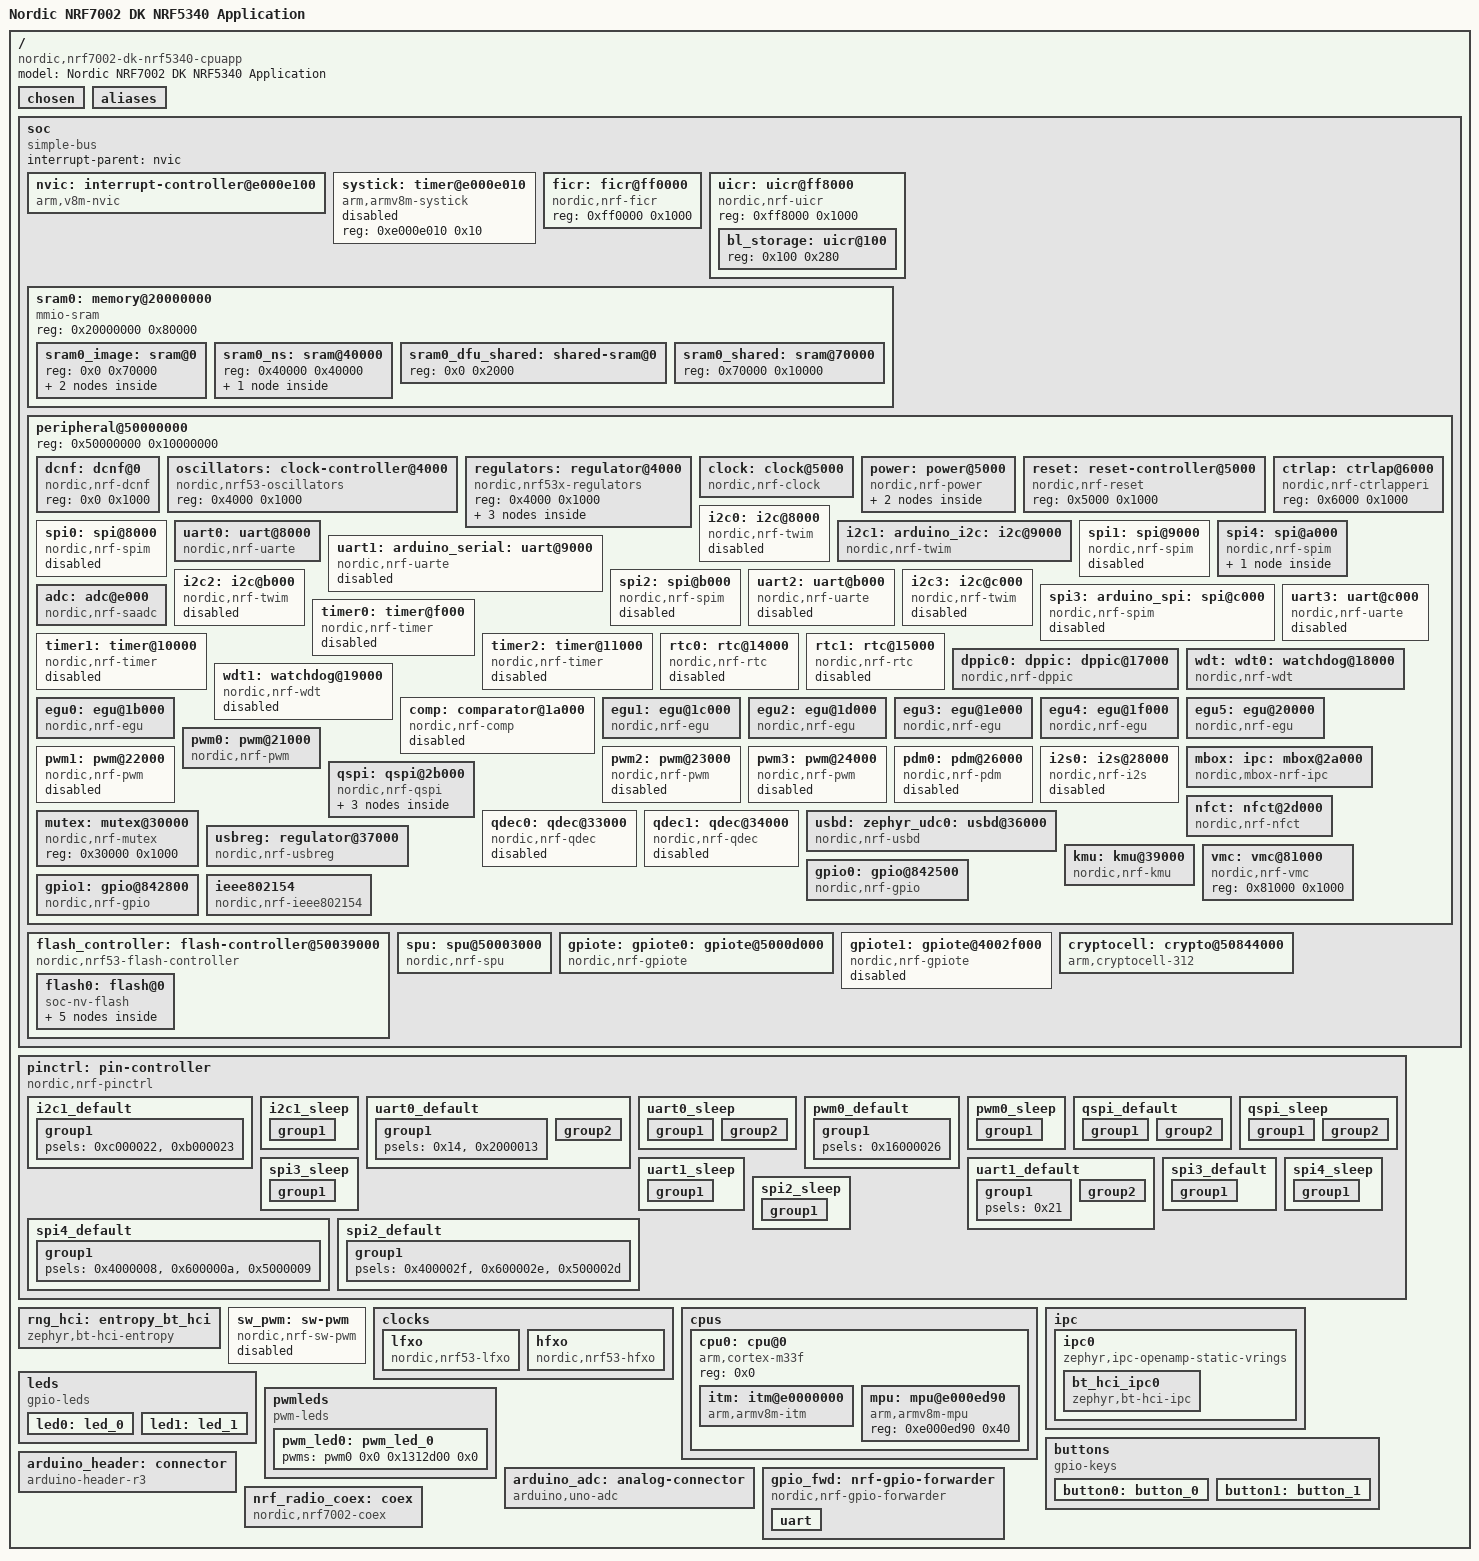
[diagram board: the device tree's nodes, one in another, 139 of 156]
/dts-v1/;

/* node '/' defined in zephyr/dts/common/skeleton.dtsi:9 */
/ {
	#address-cells = < 0x1 >;                        /* in zephyr/dts/common/skeleton.dtsi:10 */
	#size-cells = < 0x1 >;                           /* in zephyr/dts/common/skeleton.dtsi:11 */
	model = "Nordic NRF7002 DK NRF5340 Application"; /* in zephyr/boards/nordic/nrf7002dk/nrf7002dk_nrf5340_cpuapp.dts:13 */
	compatible = "nordic,nrf7002-dk-nrf5340-cpuapp"; /* in zephyr/boards/nordic/nrf7002dk/nrf7002dk_nrf5340_cpuapp.dts:14 */

	/* node '/chosen' defined in zephyr/dts/common/skeleton.dtsi:13 */
	chosen {
		zephyr,entropy = &cryptocell;                 /* in zephyr/dts/arm/nordic/nrf5340_cpuapp.dtsi:38 */
		zephyr,flash-controller = &flash_controller;  /* in zephyr/dts/arm/nordic/nrf5340_cpuapp.dtsi:39 */
		zephyr,console = &uart0;                      /* in zephyr/boards/nordic/nrf7002dk/nrf5340_cpuapp_common.dtsi:12 */
		zephyr,shell-uart = &uart0;                   /* in zephyr/boards/nordic/nrf7002dk/nrf5340_cpuapp_common.dtsi:13 */
		zephyr,uart-mcumgr = &uart0;                  /* in zephyr/boards/nordic/nrf7002dk/nrf5340_cpuapp_common.dtsi:14 */
		zephyr,bt-mon-uart = &uart0;                  /* in zephyr/boards/nordic/nrf7002dk/nrf5340_cpuapp_common.dtsi:15 */
		zephyr,bt-c2h-uart = &uart0;                  /* in zephyr/boards/nordic/nrf7002dk/nrf5340_cpuapp_common.dtsi:16 */
		zephyr,bt-hci = &bt_hci_ipc0;                 /* in zephyr/boards/nordic/nrf7002dk/nrf5340_cpuapp_common.dtsi:17 */
		nordic,802154-spinel-ipc = &ipc0;             /* in zephyr/boards/nordic/nrf7002dk/nrf5340_cpuapp_common.dtsi:18 */
		zephyr,ieee802154 = &ieee802154;              /* in zephyr/boards/nordic/nrf7002dk/nrf5340_cpuapp_common.dtsi:19 */
		zephyr,sram = &sram0_image;                   /* in zephyr/boards/nordic/nrf7002dk/nrf7002dk_nrf5340_cpuapp.dts:17 */
		zephyr,flash = &flash0;                       /* in zephyr/boards/nordic/nrf7002dk/nrf7002dk_nrf5340_cpuapp.dts:18 */
		zephyr,sram-secure-partition = &sram0_s;      /* in zephyr/boards/nordic/nrf7002dk/nrf7002dk_nrf5340_cpuapp.dts:20 */
		zephyr,sram-non-secure-partition = &sram0_ns; /* in zephyr/boards/nordic/nrf7002dk/nrf7002dk_nrf5340_cpuapp.dts:21 */
		zephyr,wifi = &wlan0;                         /* in zephyr/boards/nordic/nrf7002dk/nrf7002dk_nrf5340_cpuapp.dts:22 */
		zephyr,ipc_shm = &sram0_shared;               /* in zephyr/dts/vendor/nordic/nrf5340_shared_sram_partition.dtsi:22 */
		zephyr,code-partition = &boot_partition;      /* in bootloader/mcuboot/boot/zephyr/app.overlay:3 */
	};

	/* node '/aliases' defined in zephyr/dts/common/skeleton.dtsi:15 */
	aliases {
		led0 = &led0;               /* in zephyr/boards/nordic/nrf7002dk/nrf5340_cpuapp_common.dtsi:111 */
		led1 = &led1;               /* in zephyr/boards/nordic/nrf7002dk/nrf5340_cpuapp_common.dtsi:112 */
		pwm-led0 = &pwm_led0;       /* in zephyr/boards/nordic/nrf7002dk/nrf5340_cpuapp_common.dtsi:113 */
		sw0 = &button0;             /* in zephyr/boards/nordic/nrf7002dk/nrf5340_cpuapp_common.dtsi:114 */
		sw1 = &button1;             /* in zephyr/boards/nordic/nrf7002dk/nrf5340_cpuapp_common.dtsi:115 */
		mcuboot-button0 = &button0; /* in zephyr/boards/nordic/nrf7002dk/nrf5340_cpuapp_common.dtsi:116 */
		mcuboot-led0 = &led0;       /* in zephyr/boards/nordic/nrf7002dk/nrf5340_cpuapp_common.dtsi:117 */
		watchdog0 = &wdt0;          /* in zephyr/boards/nordic/nrf7002dk/nrf5340_cpuapp_common.dtsi:118 */
	};

	/* node '/soc' defined in zephyr/dts/arm/armv8-m.dtsi:6 */
	soc {
		#address-cells = < 0x1 >;     /* in zephyr/dts/arm/armv8-m.dtsi:7 */
		#size-cells = < 0x1 >;        /* in zephyr/dts/arm/armv8-m.dtsi:8 */
		interrupt-parent = < &nvic >; /* in zephyr/dts/arm/armv8-m.dtsi:10 */
		ranges;                       /* in zephyr/dts/arm/armv8-m.dtsi:11 */
		compatible = "simple-bus";    /* in zephyr/dts/arm/nordic/nrf5340_cpuapp.dtsi:43 */

		/* node '/soc/interrupt-controller@e000e100' defined in zephyr/dts/arm/armv8-m.dtsi:13 */
		nvic: interrupt-controller@e000e100 {
			#address-cells = < 0x1 >;            /* in zephyr/dts/arm/armv8-m.dtsi:14 */
			compatible = "arm,v8m-nvic";         /* in zephyr/dts/arm/armv8-m.dtsi:15 */
			reg = < 0xe000e100 0xc00 >;          /* in zephyr/dts/arm/armv8-m.dtsi:16 */
			interrupt-controller;                /* in zephyr/dts/arm/armv8-m.dtsi:17 */
			#interrupt-cells = < 0x2 >;          /* in zephyr/dts/arm/armv8-m.dtsi:18 */
			arm,num-irq-priority-bits = < 0x3 >; /* in zephyr/dts/arm/nordic/nrf5340_cpuapp.dtsi:152 */
			phandle = < 0x1 >;                   /* in zephyr/dts/arm/armv8-m.dtsi:10 */
		};

		/* node '/soc/timer@e000e010' defined in zephyr/dts/arm/armv8-m.dtsi:21 */
		systick: timer@e000e010 {
			compatible = "arm,armv8m-systick"; /* in zephyr/dts/arm/armv8-m.dtsi:22 */
			reg = < 0xe000e010 0x10 >;         /* in zephyr/dts/arm/armv8-m.dtsi:23 */
			status = "disabled";               /* in zephyr/dts/arm/nordic/nrf5340_cpuapp.dtsi:157 */
		};

		/* node '/soc/ficr@ff0000' defined in zephyr/dts/arm/nordic/nrf5340_cpuapp.dtsi:45 */
		ficr: ficr@ff0000 {
			compatible = "nordic,nrf-ficr"; /* in zephyr/dts/arm/nordic/nrf5340_cpuapp.dtsi:46 */
			reg = < 0xff0000 0x1000 >;      /* in zephyr/dts/arm/nordic/nrf5340_cpuapp.dtsi:47 */
			#nordic,ficr-cells = < 0x1 >;   /* in zephyr/dts/arm/nordic/nrf5340_cpuapp.dtsi:48 */
			status = "okay";                /* in zephyr/dts/arm/nordic/nrf5340_cpuapp.dtsi:49 */
		};

		/* node '/soc/uicr@ff8000' defined in zephyr/dts/arm/nordic/nrf5340_cpuapp.dtsi:52 */
		uicr: uicr@ff8000 {
			compatible = "nordic,nrf-uicr";   /* in zephyr/dts/arm/nordic/nrf5340_cpuapp.dtsi:53 */
			reg = < 0xff8000 0x1000 >;        /* in zephyr/dts/arm/nordic/nrf5340_cpuapp.dtsi:54 */
			ranges = < 0x0 0xff8000 0x1000 >; /* in zephyr/dts/arm/nordic/nrf5340_cpuapp.dtsi:55 */
			status = "okay";                  /* in zephyr/dts/arm/nordic/nrf5340_cpuapp.dtsi:56 */
			#address-cells = < 0x1 >;         /* in zephyr/dts/arm/nordic/nrf5340_cpuapp.dtsi:57 */
			#size-cells = < 0x1 >;            /* in zephyr/dts/arm/nordic/nrf5340_cpuapp.dtsi:58 */

			/* node '/soc/uicr@ff8000/uicr@100' defined in zephyr/dts/vendor/nordic/nrf5340_cpuapp_partition.dtsi:43 */
			bl_storage: uicr@100 {
				reg = < 0x100 0x280 >; /* in zephyr/dts/vendor/nordic/nrf5340_cpuapp_partition.dtsi:44 */
			};
		};

		/* node '/soc/memory@20000000' defined in zephyr/dts/arm/nordic/nrf5340_cpuapp.dtsi:61 */
		sram0: memory@20000000 {
			compatible = "mmio-sram";            /* in zephyr/dts/arm/nordic/nrf5340_cpuapp.dtsi:62 */
			#address-cells = < 0x1 >;            /* in zephyr/dts/arm/nordic/nrf5340_cpuapp.dtsi:63 */
			#size-cells = < 0x1 >;               /* in zephyr/dts/arm/nordic/nrf5340_cpuapp.dtsi:64 */
			reg = < 0x20000000 0x80000 >;        /* in zephyr/dts/arm/nordic/nrf5340_cpuapp_qkaa.dtsi:11 */
			ranges = < 0x0 0x20000000 0x80000 >; /* in zephyr/dts/arm/nordic/nrf5340_cpuapp_qkaa.dtsi:12 */

			/* node '/soc/memory@20000000/sram@0' defined in zephyr/dts/vendor/nordic/nrf5340_sram_partition.dtsi:16 */
			sram0_image: sram@0 {
				reg = < 0x0 0x70000 >;        /* in zephyr/dts/vendor/nordic/nrf5340_sram_partition.dtsi:18 */
				ranges = < 0x0 0x0 0x70000 >; /* in zephyr/dts/vendor/nordic/nrf5340_sram_partition.dtsi:19 */
				#address-cells = < 0x1 >;     /* in zephyr/dts/vendor/nordic/nrf5340_sram_partition.dtsi:20 */
				#size-cells = < 0x1 >;        /* in zephyr/dts/vendor/nordic/nrf5340_sram_partition.dtsi:21 */

				/* node '/soc/memory@20000000/sram@0/sram0_image@0' defined in zephyr/dts/vendor/nordic/nrf5340_sram_partition.dtsi:23 */
				sram0_s: sram0_image@0 {
					reg = < 0x0 0x40000 >; /* in zephyr/dts/vendor/nordic/nrf5340_sram_partition.dtsi:25 */
				};

				/* node '/soc/memory@20000000/sram@0/sram@2000' defined in zephyr/dts/vendor/nordic/nrf5340_sram_partition.dtsi:28 */
				sram0_offset_for_dfu: sram@2000 {
					reg = < 0x2000 0x6e000 >;        /* in zephyr/dts/vendor/nordic/nrf5340_sram_partition.dtsi:29 */
					ranges = < 0x0 0x2000 0x6e000 >; /* in zephyr/dts/vendor/nordic/nrf5340_sram_partition.dtsi:30 */
					#address-cells = < 0x1 >;        /* in zephyr/dts/vendor/nordic/nrf5340_sram_partition.dtsi:31 */
					#size-cells = < 0x1 >;           /* in zephyr/dts/vendor/nordic/nrf5340_sram_partition.dtsi:32 */
				};
			};

			/* node '/soc/memory@20000000/sram@40000' defined in zephyr/dts/vendor/nordic/nrf5340_sram_partition.dtsi:40 */
			sram0_ns: sram@40000 {
				reg = < 0x40000 0x40000 >;        /* in zephyr/dts/vendor/nordic/nrf5340_sram_partition.dtsi:42 */
				ranges = < 0x0 0x40000 0x40000 >; /* in zephyr/dts/vendor/nordic/nrf5340_sram_partition.dtsi:43 */
				#address-cells = < 0x1 >;         /* in zephyr/dts/vendor/nordic/nrf5340_sram_partition.dtsi:44 */
				#size-cells = < 0x1 >;            /* in zephyr/dts/vendor/nordic/nrf5340_sram_partition.dtsi:45 */

				/* node '/soc/memory@20000000/sram@40000/sram0_ns@0' defined in zephyr/dts/vendor/nordic/nrf5340_sram_partition.dtsi:47 */
				sram0_ns_app: sram0_ns@0 {
					reg = < 0x0 0x30000 >; /* in zephyr/dts/vendor/nordic/nrf5340_sram_partition.dtsi:49 */
				};
			};

			/* node '/soc/memory@20000000/shared-sram@0' defined in zephyr/dts/vendor/nordic/nrf5340_shared_sram_partition.dtsi:27 */
			sram0_dfu_shared: shared-sram@0 {
				reg = < 0x0 0x2000 >; /* in zephyr/dts/vendor/nordic/nrf5340_shared_sram_partition.dtsi:28 */
			};

			/* node '/soc/memory@20000000/sram@70000' defined in zephyr/dts/vendor/nordic/nrf5340_shared_sram_partition.dtsi:31 */
			sram0_shared: sram@70000 {
				reg = < 0x70000 0x10000 >; /* in zephyr/dts/vendor/nordic/nrf5340_shared_sram_partition.dtsi:33 */
				phandle = < 0x15 >;        /* in zephyr/dts/arm/nordic/nrf5340_cpuapp_ipc.dtsi:9 */
			};
		};

		/* node '/soc/peripheral@50000000' defined in zephyr/dts/arm/nordic/nrf5340_cpuapp.dtsi:67 */
		peripheral@50000000 {
			reg = < 0x50000000 0x10000000 >;               /* in zephyr/dts/arm/nordic/nrf5340_cpuapp.dtsi:68 */
			#address-cells = < 0x1 >;                      /* in zephyr/dts/arm/nordic/nrf5340_cpuapp.dtsi:69 */
			#size-cells = < 0x1 >;                         /* in zephyr/dts/arm/nordic/nrf5340_cpuapp.dtsi:70 */
			ranges = < 0x0 0x50000000 0x10000000 >,
			         < 0x10000000 0x10000000 0x10000000 >; /* in zephyr/dts/arm/nordic/nrf5340_cpuapp.dtsi:71 */

			/* node '/soc/peripheral@50000000/dcnf@0' defined in zephyr/dts/arm/nordic/nrf5340_cpuapp_peripherals.dtsi:9 */
			dcnf: dcnf@0 {
				compatible = "nordic,nrf-dcnf"; /* in zephyr/dts/arm/nordic/nrf5340_cpuapp_peripherals.dtsi:10 */
				reg = < 0x0 0x1000 >;           /* in zephyr/dts/arm/nordic/nrf5340_cpuapp_peripherals.dtsi:11 */
				status = "okay";                /* in zephyr/dts/arm/nordic/nrf5340_cpuapp_peripherals.dtsi:12 */
			};

			/* node '/soc/peripheral@50000000/clock-controller@4000' defined in zephyr/dts/arm/nordic/nrf5340_cpuapp_peripherals.dtsi:15 */
			oscillators: clock-controller@4000 {
				compatible = "nordic,nrf53-oscillators"; /* in zephyr/dts/arm/nordic/nrf5340_cpuapp_peripherals.dtsi:16 */
				reg = < 0x4000 0x1000 >;                 /* in zephyr/dts/arm/nordic/nrf5340_cpuapp_peripherals.dtsi:17 */
			};

			/* node '/soc/peripheral@50000000/regulator@4000' defined in zephyr/dts/arm/nordic/nrf5340_cpuapp_peripherals.dtsi:20 */
			regulators: regulator@4000 {
				compatible = "nordic,nrf53x-regulators"; /* in zephyr/dts/arm/nordic/nrf5340_cpuapp_peripherals.dtsi:21 */
				reg = < 0x4000 0x1000 >;                 /* in zephyr/dts/arm/nordic/nrf5340_cpuapp_peripherals.dtsi:22 */
				status = "okay";                         /* in zephyr/dts/arm/nordic/nrf5340_cpuapp_peripherals.dtsi:23 */
				#address-cells = < 0x1 >;                /* in zephyr/dts/arm/nordic/nrf5340_cpuapp_peripherals.dtsi:24 */
				#size-cells = < 0x1 >;                   /* in zephyr/dts/arm/nordic/nrf5340_cpuapp_peripherals.dtsi:25 */

				/* node '/soc/peripheral@50000000/regulator@4000/regulator@4704' defined in zephyr/dts/arm/nordic/nrf5340_cpuapp_peripherals.dtsi:27 */
				vregmain: regulator@4704 {
					compatible = "nordic,nrf5x-regulator"; /* in zephyr/dts/arm/nordic/nrf5340_cpuapp_peripherals.dtsi:28 */
					reg = < 0x4704 0x1 >;                  /* in zephyr/dts/arm/nordic/nrf5340_cpuapp_peripherals.dtsi:29 */
					status = "okay";                       /* in zephyr/dts/arm/nordic/nrf5340_cpuapp_peripherals.dtsi:30 */
					regulator-name = "VREGMAIN";           /* in zephyr/dts/arm/nordic/nrf5340_cpuapp_peripherals.dtsi:31 */
					regulator-initial-mode = < 0x1 >;      /* in zephyr/boards/nordic/nrf7002dk/nrf5340_cpuapp_common.dtsi:132 */
				};

				/* node '/soc/peripheral@50000000/regulator@4000/regulator@4904' defined in zephyr/dts/arm/nordic/nrf5340_cpuapp_peripherals.dtsi:35 */
				vregradio: regulator@4904 {
					compatible = "nordic,nrf5x-regulator"; /* in zephyr/dts/arm/nordic/nrf5340_cpuapp_peripherals.dtsi:36 */
					reg = < 0x4904 0x1 >;                  /* in zephyr/dts/arm/nordic/nrf5340_cpuapp_peripherals.dtsi:37 */
					status = "okay";                       /* in zephyr/dts/arm/nordic/nrf5340_cpuapp_peripherals.dtsi:38 */
					regulator-name = "VREGRADIO";          /* in zephyr/dts/arm/nordic/nrf5340_cpuapp_peripherals.dtsi:39 */
					regulator-initial-mode = < 0x1 >;      /* in zephyr/boards/nordic/nrf7002dk/nrf5340_cpuapp_common.dtsi:136 */
				};

				/* node '/soc/peripheral@50000000/regulator@4000/regulator@4b00' defined in zephyr/dts/arm/nordic/nrf5340_cpuapp_peripherals.dtsi:43 */
				vregh: regulator@4b00 {
					compatible = "nordic,nrf53x-regulator-hv"; /* in zephyr/dts/arm/nordic/nrf5340_cpuapp_peripherals.dtsi:44 */
					reg = < 0x4b00 0x44 >;                     /* in zephyr/dts/arm/nordic/nrf5340_cpuapp_peripherals.dtsi:45 */
					regulator-name = "VREGH";                  /* in zephyr/dts/arm/nordic/nrf5340_cpuapp_peripherals.dtsi:47 */
					status = "okay";                           /* in zephyr/boards/nordic/nrf7002dk/nrf5340_cpuapp_common.dtsi:140 */
				};
			};

			/* node '/soc/peripheral@50000000/clock@5000' defined in zephyr/dts/arm/nordic/nrf5340_cpuapp_peripherals.dtsi:51 */
			clock: clock@5000 {
				compatible = "nordic,nrf-clock"; /* in zephyr/dts/arm/nordic/nrf5340_cpuapp_peripherals.dtsi:52 */
				reg = < 0x5000 0x1000 >;         /* in zephyr/dts/arm/nordic/nrf5340_cpuapp_peripherals.dtsi:53 */
				interrupts = < 0x5 0x1 >;        /* in zephyr/dts/arm/nordic/nrf5340_cpuapp_peripherals.dtsi:54 */
				status = "okay";                 /* in zephyr/dts/arm/nordic/nrf5340_cpuapp_peripherals.dtsi:55 */
			};

			/* node '/soc/peripheral@50000000/power@5000' defined in zephyr/dts/arm/nordic/nrf5340_cpuapp_peripherals.dtsi:58 */
			power: power@5000 {
				compatible = "nordic,nrf-power"; /* in zephyr/dts/arm/nordic/nrf5340_cpuapp_peripherals.dtsi:59 */
				reg = < 0x5000 0x1000 >;         /* in zephyr/dts/arm/nordic/nrf5340_cpuapp_peripherals.dtsi:60 */
				ranges = < 0x0 0x5000 0x1000 >;  /* in zephyr/dts/arm/nordic/nrf5340_cpuapp_peripherals.dtsi:61 */
				interrupts = < 0x5 0x1 >;        /* in zephyr/dts/arm/nordic/nrf5340_cpuapp_peripherals.dtsi:62 */
				status = "okay";                 /* in zephyr/dts/arm/nordic/nrf5340_cpuapp_peripherals.dtsi:63 */
				#address-cells = < 0x1 >;        /* in zephyr/dts/arm/nordic/nrf5340_cpuapp_peripherals.dtsi:64 */
				#size-cells = < 0x1 >;           /* in zephyr/dts/arm/nordic/nrf5340_cpuapp_peripherals.dtsi:65 */

				/* node '/soc/peripheral@50000000/power@5000/gpregret1@51c' defined in zephyr/dts/arm/nordic/nrf5340_cpuapp_peripherals.dtsi:67 */
				gpregret1: gpregret1@51c {
					#address-cells = < 0x1 >;           /* in zephyr/dts/arm/nordic/nrf5340_cpuapp_peripherals.dtsi:68 */
					#size-cells = < 0x1 >;              /* in zephyr/dts/arm/nordic/nrf5340_cpuapp_peripherals.dtsi:69 */
					compatible = "nordic,nrf-gpregret"; /* in zephyr/dts/arm/nordic/nrf5340_cpuapp_peripherals.dtsi:70 */
					reg = < 0x51c 0x1 >;                /* in zephyr/dts/arm/nordic/nrf5340_cpuapp_peripherals.dtsi:71 */
					status = "okay";                    /* in zephyr/dts/arm/nordic/nrf5340_cpuapp_peripherals.dtsi:72 */
				};

				/* node '/soc/peripheral@50000000/power@5000/gpregret2@520' defined in zephyr/dts/arm/nordic/nrf5340_cpuapp_peripherals.dtsi:75 */
				gpregret2: gpregret2@520 {
					#address-cells = < 0x1 >;           /* in zephyr/dts/arm/nordic/nrf5340_cpuapp_peripherals.dtsi:76 */
					#size-cells = < 0x1 >;              /* in zephyr/dts/arm/nordic/nrf5340_cpuapp_peripherals.dtsi:77 */
					compatible = "nordic,nrf-gpregret"; /* in zephyr/dts/arm/nordic/nrf5340_cpuapp_peripherals.dtsi:78 */
					reg = < 0x520 0x1 >;                /* in zephyr/dts/arm/nordic/nrf5340_cpuapp_peripherals.dtsi:79 */
					status = "okay";                    /* in zephyr/dts/arm/nordic/nrf5340_cpuapp_peripherals.dtsi:80 */
				};
			};

			/* node '/soc/peripheral@50000000/reset-controller@5000' defined in zephyr/dts/arm/nordic/nrf5340_cpuapp_peripherals.dtsi:84 */
			reset: reset-controller@5000 {
				compatible = "nordic,nrf-reset"; /* in zephyr/dts/arm/nordic/nrf5340_cpuapp_peripherals.dtsi:85 */
				reg = < 0x5000 0x1000 >;         /* in zephyr/dts/arm/nordic/nrf5340_cpuapp_peripherals.dtsi:86 */
				status = "okay";                 /* in zephyr/dts/arm/nordic/nrf5340_cpuapp_peripherals.dtsi:87 */
			};

			/* node '/soc/peripheral@50000000/ctrlap@6000' defined in zephyr/dts/arm/nordic/nrf5340_cpuapp_peripherals.dtsi:90 */
			ctrlap: ctrlap@6000 {
				compatible = "nordic,nrf-ctrlapperi"; /* in zephyr/dts/arm/nordic/nrf5340_cpuapp_peripherals.dtsi:91 */
				reg = < 0x6000 0x1000 >;              /* in zephyr/dts/arm/nordic/nrf5340_cpuapp_peripherals.dtsi:92 */
				status = "okay";                      /* in zephyr/dts/arm/nordic/nrf5340_cpuapp_peripherals.dtsi:93 */
			};

			/* node '/soc/peripheral@50000000/i2c@8000' defined in zephyr/dts/arm/nordic/nrf5340_cpuapp_peripherals.dtsi:96 */
			i2c0: i2c@8000 {
				compatible = "nordic,nrf-twim"; /* in zephyr/dts/arm/nordic/nrf5340_cpuapp_peripherals.dtsi:102 */
				#address-cells = < 0x1 >;       /* in zephyr/dts/arm/nordic/nrf5340_cpuapp_peripherals.dtsi:103 */
				#size-cells = < 0x0 >;          /* in zephyr/dts/arm/nordic/nrf5340_cpuapp_peripherals.dtsi:104 */
				reg = < 0x8000 0x1000 >;        /* in zephyr/dts/arm/nordic/nrf5340_cpuapp_peripherals.dtsi:105 */
				interrupts = < 0x8 0x1 >;       /* in zephyr/dts/arm/nordic/nrf5340_cpuapp_peripherals.dtsi:106 */
				easydma-maxcnt-bits = < 0x10 >; /* in zephyr/dts/arm/nordic/nrf5340_cpuapp_peripherals.dtsi:107 */
				status = "disabled";            /* in zephyr/dts/arm/nordic/nrf5340_cpuapp_peripherals.dtsi:108 */
				zephyr,pm-device-runtime-auto;  /* in zephyr/dts/arm/nordic/nrf5340_cpuapp_peripherals.dtsi:109 */
			};

			/* node '/soc/peripheral@50000000/spi@8000' defined in zephyr/dts/arm/nordic/nrf5340_cpuapp_peripherals.dtsi:112 */
			spi0: spi@8000 {
				compatible = "nordic,nrf-spim"; /* in zephyr/dts/arm/nordic/nrf5340_cpuapp_peripherals.dtsi:119 */
				#address-cells = < 0x1 >;       /* in zephyr/dts/arm/nordic/nrf5340_cpuapp_peripherals.dtsi:120 */
				#size-cells = < 0x0 >;          /* in zephyr/dts/arm/nordic/nrf5340_cpuapp_peripherals.dtsi:121 */
				reg = < 0x8000 0x1000 >;        /* in zephyr/dts/arm/nordic/nrf5340_cpuapp_peripherals.dtsi:122 */
				interrupts = < 0x8 0x1 >;       /* in zephyr/dts/arm/nordic/nrf5340_cpuapp_peripherals.dtsi:123 */
				max-frequency = < 0x7a1200 >;   /* in zephyr/dts/arm/nordic/nrf5340_cpuapp_peripherals.dtsi:124 */
				easydma-maxcnt-bits = < 0x10 >; /* in zephyr/dts/arm/nordic/nrf5340_cpuapp_peripherals.dtsi:125 */
				status = "disabled";            /* in zephyr/dts/arm/nordic/nrf5340_cpuapp_peripherals.dtsi:126 */
			};

			/* node '/soc/peripheral@50000000/uart@8000' defined in zephyr/dts/arm/nordic/nrf5340_cpuapp_peripherals.dtsi:129 */
			uart0: uart@8000 {
				compatible = "nordic,nrf-uarte"; /* in zephyr/dts/arm/nordic/nrf5340_cpuapp_peripherals.dtsi:130 */
				reg = < 0x8000 0x1000 >;         /* in zephyr/dts/arm/nordic/nrf5340_cpuapp_peripherals.dtsi:131 */
				interrupts = < 0x8 0x1 >;        /* in zephyr/dts/arm/nordic/nrf5340_cpuapp_peripherals.dtsi:132 */
				status = "okay";                 /* in zephyr/boards/nordic/nrf7002dk/nrf5340_cpuapp_common.dtsi:177 */
				current-speed = < 0x1c200 >;     /* in zephyr/boards/nordic/nrf7002dk/nrf5340_cpuapp_common.dtsi:178 */
				pinctrl-0 = < &uart0_default >;  /* in zephyr/boards/nordic/nrf7002dk/nrf5340_cpuapp_common.dtsi:179 */
				pinctrl-1 = < &uart0_sleep >;    /* in zephyr/boards/nordic/nrf7002dk/nrf5340_cpuapp_common.dtsi:180 */
				pinctrl-names = "default",
				                "sleep";         /* in zephyr/boards/nordic/nrf7002dk/nrf5340_cpuapp_common.dtsi:181 */
			};

			/* node '/soc/peripheral@50000000/i2c@9000' defined in zephyr/dts/arm/nordic/nrf5340_cpuapp_peripherals.dtsi:136 */
			i2c1: arduino_i2c: i2c@9000 {
				#address-cells = < 0x1 >;       /* in zephyr/dts/arm/nordic/nrf5340_cpuapp_peripherals.dtsi:144 */
				#size-cells = < 0x0 >;          /* in zephyr/dts/arm/nordic/nrf5340_cpuapp_peripherals.dtsi:145 */
				reg = < 0x9000 0x1000 >;        /* in zephyr/dts/arm/nordic/nrf5340_cpuapp_peripherals.dtsi:146 */
				interrupts = < 0x9 0x1 >;       /* in zephyr/dts/arm/nordic/nrf5340_cpuapp_peripherals.dtsi:147 */
				easydma-maxcnt-bits = < 0x10 >; /* in zephyr/dts/arm/nordic/nrf5340_cpuapp_peripherals.dtsi:148 */
				zephyr,pm-device-runtime-auto;  /* in zephyr/dts/arm/nordic/nrf5340_cpuapp_peripherals.dtsi:150 */
				compatible = "nordic,nrf-twim"; /* in zephyr/boards/nordic/nrf7002dk/nrf5340_cpuapp_common.dtsi:169 */
				status = "okay";                /* in zephyr/boards/nordic/nrf7002dk/nrf5340_cpuapp_common.dtsi:170 */
				pinctrl-0 = < &i2c1_default >;  /* in zephyr/boards/nordic/nrf7002dk/nrf5340_cpuapp_common.dtsi:171 */
				pinctrl-1 = < &i2c1_sleep >;    /* in zephyr/boards/nordic/nrf7002dk/nrf5340_cpuapp_common.dtsi:172 */
				pinctrl-names = "default",
				                "sleep";        /* in zephyr/boards/nordic/nrf7002dk/nrf5340_cpuapp_common.dtsi:173 */
			};

			/* node '/soc/peripheral@50000000/spi@9000' defined in zephyr/dts/arm/nordic/nrf5340_cpuapp_peripherals.dtsi:153 */
			spi1: spi@9000 {
				compatible = "nordic,nrf-spim"; /* in zephyr/dts/arm/nordic/nrf5340_cpuapp_peripherals.dtsi:160 */
				#address-cells = < 0x1 >;       /* in zephyr/dts/arm/nordic/nrf5340_cpuapp_peripherals.dtsi:161 */
				#size-cells = < 0x0 >;          /* in zephyr/dts/arm/nordic/nrf5340_cpuapp_peripherals.dtsi:162 */
				reg = < 0x9000 0x1000 >;        /* in zephyr/dts/arm/nordic/nrf5340_cpuapp_peripherals.dtsi:163 */
				interrupts = < 0x9 0x1 >;       /* in zephyr/dts/arm/nordic/nrf5340_cpuapp_peripherals.dtsi:164 */
				max-frequency = < 0x7a1200 >;   /* in zephyr/dts/arm/nordic/nrf5340_cpuapp_peripherals.dtsi:165 */
				easydma-maxcnt-bits = < 0x10 >; /* in zephyr/dts/arm/nordic/nrf5340_cpuapp_peripherals.dtsi:166 */
				status = "disabled";            /* in zephyr/dts/arm/nordic/nrf5340_cpuapp_peripherals.dtsi:167 */
			};

			/* node '/soc/peripheral@50000000/uart@9000' defined in zephyr/dts/arm/nordic/nrf5340_cpuapp_peripherals.dtsi:170 */
			uart1: arduino_serial: uart@9000 {
				reg = < 0x9000 0x1000 >;         /* in zephyr/dts/arm/nordic/nrf5340_cpuapp_peripherals.dtsi:172 */
				interrupts = < 0x9 0x1 >;        /* in zephyr/dts/arm/nordic/nrf5340_cpuapp_peripherals.dtsi:173 */
				status = "disabled";             /* in zephyr/dts/arm/nordic/nrf5340_cpuapp_peripherals.dtsi:174 */
				compatible = "nordic,nrf-uarte"; /* in zephyr/boards/nordic/nrf7002dk/nrf5340_cpuapp_common.dtsi:223 */
				current-speed = < 0x1c200 >;     /* in zephyr/boards/nordic/nrf7002dk/nrf5340_cpuapp_common.dtsi:224 */
				pinctrl-0 = < &uart1_default >;  /* in zephyr/boards/nordic/nrf7002dk/nrf5340_cpuapp_common.dtsi:225 */
				pinctrl-1 = < &uart1_sleep >;    /* in zephyr/boards/nordic/nrf7002dk/nrf5340_cpuapp_common.dtsi:226 */
				pinctrl-names = "default",
				                "sleep";         /* in zephyr/boards/nordic/nrf7002dk/nrf5340_cpuapp_common.dtsi:227 */
			};

			/* node '/soc/peripheral@50000000/spi@a000' defined in zephyr/dts/arm/nordic/nrf5340_cpuapp_peripherals.dtsi:177 */
			spi4: spi@a000 {
				#address-cells = < 0x1 >;       /* in zephyr/dts/arm/nordic/nrf5340_cpuapp_peripherals.dtsi:179 */
				#size-cells = < 0x0 >;          /* in zephyr/dts/arm/nordic/nrf5340_cpuapp_peripherals.dtsi:180 */
				reg = < 0xa000 0x1000 >;        /* in zephyr/dts/arm/nordic/nrf5340_cpuapp_peripherals.dtsi:181 */
				interrupts = < 0xa 0x1 >;       /* in zephyr/dts/arm/nordic/nrf5340_cpuapp_peripherals.dtsi:182 */
				max-frequency = < 0x1e84800 >;  /* in zephyr/dts/arm/nordic/nrf5340_cpuapp_peripherals.dtsi:183 */
				easydma-maxcnt-bits = < 0x10 >; /* in zephyr/dts/arm/nordic/nrf5340_cpuapp_peripherals.dtsi:184 */
				rx-delay-supported;             /* in zephyr/dts/arm/nordic/nrf5340_cpuapp_peripherals.dtsi:185 */
				rx-delay = < 0x2 >;             /* in zephyr/dts/arm/nordic/nrf5340_cpuapp_peripherals.dtsi:186 */
				compatible = "nordic,nrf-spim"; /* in zephyr/boards/nordic/nrf7002dk/nrf5340_cpuapp_common.dtsi:192 */
				status = "okay";                /* in zephyr/boards/nordic/nrf7002dk/nrf5340_cpuapp_common.dtsi:193 */
				pinctrl-0 = < &spi4_default >;  /* in zephyr/boards/nordic/nrf7002dk/nrf5340_cpuapp_common.dtsi:194 */
				pinctrl-1 = < &spi4_sleep >;    /* in zephyr/boards/nordic/nrf7002dk/nrf5340_cpuapp_common.dtsi:195 */
				pinctrl-names = "default",
				                "sleep";        /* in zephyr/boards/nordic/nrf7002dk/nrf5340_cpuapp_common.dtsi:196 */
				cs-gpios = < &gpio0 0xb 0x1 >;  /* in zephyr/boards/nordic/nrf7002dk/nrf5340_cpuapp_common.dtsi:197 */

				/* node '/soc/peripheral@50000000/spi@a000/mx25r6435f@0' defined in zephyr/boards/nordic/nrf7002dk/nrf5340_cpuapp_common.dtsi:199 */
				mx25r64: mx25r6435f@0 {
					compatible = "jedec,spi-nor";                                                                 /* in zephyr/boards/nordic/nrf7002dk/nrf5340_cpuapp_common.dtsi:200 */
					reg = < 0x0 >;                                                                                /* in zephyr/boards/nordic/nrf7002dk/nrf5340_cpuapp_common.dtsi:201 */
					spi-max-frequency = < 0x1f78a40 >;                                                            /* in zephyr/boards/nordic/nrf7002dk/nrf5340_cpuapp_common.dtsi:202 */
					jedec-id = [ C2 28 17 ];                                                                      /* in zephyr/boards/nordic/nrf7002dk/nrf5340_cpuapp_common.dtsi:203 */
					sfdp-bfp = [ E5 20 F1 FF FF FF FF 03 44 EB 08 6B 08 3B 04 BB EE FF FF FF FF FF 00 FF FF FF 00
					             FF 0C 20 0F 52 10 D8 00 FF 23 72 F5 00 82 ED 04 CC 44 83 68 44 30 B0 30 B0 F7 C4
					             D5 5C 00 BE 29 FF F0 D0 FF FF ];                                                 /* in zephyr/boards/nordic/nrf7002dk/nrf5340_cpuapp_common.dtsi:204 */
					size = < 0x4000000 >;                                                                         /* in zephyr/boards/nordic/nrf7002dk/nrf5340_cpuapp_common.dtsi:208 */
					has-dpd;                                                                                      /* in zephyr/boards/nordic/nrf7002dk/nrf5340_cpuapp_common.dtsi:209 */
					t-enter-dpd = < 0x2710 >;                                                                     /* in zephyr/boards/nordic/nrf7002dk/nrf5340_cpuapp_common.dtsi:210 */
					t-exit-dpd = < 0x1388 >;                                                                      /* in zephyr/boards/nordic/nrf7002dk/nrf5340_cpuapp_common.dtsi:211 */
				};
			};

			/* node '/soc/peripheral@50000000/i2c@b000' defined in zephyr/dts/arm/nordic/nrf5340_cpuapp_peripherals.dtsi:190 */
			i2c2: i2c@b000 {
				compatible = "nordic,nrf-twim"; /* in zephyr/dts/arm/nordic/nrf5340_cpuapp_peripherals.dtsi:197 */
				#address-cells = < 0x1 >;       /* in zephyr/dts/arm/nordic/nrf5340_cpuapp_peripherals.dtsi:198 */
				#size-cells = < 0x0 >;          /* in zephyr/dts/arm/nordic/nrf5340_cpuapp_peripherals.dtsi:199 */
				reg = < 0xb000 0x1000 >;        /* in zephyr/dts/arm/nordic/nrf5340_cpuapp_peripherals.dtsi:200 */
				interrupts = < 0xb 0x1 >;       /* in zephyr/dts/arm/nordic/nrf5340_cpuapp_peripherals.dtsi:201 */
				easydma-maxcnt-bits = < 0x10 >; /* in zephyr/dts/arm/nordic/nrf5340_cpuapp_peripherals.dtsi:202 */
				status = "disabled";            /* in zephyr/dts/arm/nordic/nrf5340_cpuapp_peripherals.dtsi:203 */
				zephyr,pm-device-runtime-auto;  /* in zephyr/dts/arm/nordic/nrf5340_cpuapp_peripherals.dtsi:204 */
			};

			/* node '/soc/peripheral@50000000/spi@b000' defined in zephyr/dts/arm/nordic/nrf5340_cpuapp_peripherals.dtsi:207 */
			spi2: spi@b000 {
				compatible = "nordic,nrf-spim"; /* in zephyr/dts/arm/nordic/nrf5340_cpuapp_peripherals.dtsi:214 */
				#address-cells = < 0x1 >;       /* in zephyr/dts/arm/nordic/nrf5340_cpuapp_peripherals.dtsi:215 */
				#size-cells = < 0x0 >;          /* in zephyr/dts/arm/nordic/nrf5340_cpuapp_peripherals.dtsi:216 */
				reg = < 0xb000 0x1000 >;        /* in zephyr/dts/arm/nordic/nrf5340_cpuapp_peripherals.dtsi:217 */
				interrupts = < 0xb 0x1 >;       /* in zephyr/dts/arm/nordic/nrf5340_cpuapp_peripherals.dtsi:218 */
				max-frequency = < 0x7a1200 >;   /* in zephyr/dts/arm/nordic/nrf5340_cpuapp_peripherals.dtsi:219 */
				easydma-maxcnt-bits = < 0x10 >; /* in zephyr/dts/arm/nordic/nrf5340_cpuapp_peripherals.dtsi:220 */
				status = "disabled";            /* in zephyr/dts/arm/nordic/nrf5340_cpuapp_peripherals.dtsi:221 */
			};

			/* node '/soc/peripheral@50000000/uart@b000' defined in zephyr/dts/arm/nordic/nrf5340_cpuapp_peripherals.dtsi:224 */
			uart2: uart@b000 {
				compatible = "nordic,nrf-uarte"; /* in zephyr/dts/arm/nordic/nrf5340_cpuapp_peripherals.dtsi:225 */
				reg = < 0xb000 0x1000 >;         /* in zephyr/dts/arm/nordic/nrf5340_cpuapp_peripherals.dtsi:226 */
				interrupts = < 0xb 0x1 >;        /* in zephyr/dts/arm/nordic/nrf5340_cpuapp_peripherals.dtsi:227 */
				status = "disabled";             /* in zephyr/dts/arm/nordic/nrf5340_cpuapp_peripherals.dtsi:228 */
			};

			/* node '/soc/peripheral@50000000/i2c@c000' defined in zephyr/dts/arm/nordic/nrf5340_cpuapp_peripherals.dtsi:231 */
			i2c3: i2c@c000 {
				compatible = "nordic,nrf-twim"; /* in zephyr/dts/arm/nordic/nrf5340_cpuapp_peripherals.dtsi:238 */
				#address-cells = < 0x1 >;       /* in zephyr/dts/arm/nordic/nrf5340_cpuapp_peripherals.dtsi:239 */
				#size-cells = < 0x0 >;          /* in zephyr/dts/arm/nordic/nrf5340_cpuapp_peripherals.dtsi:240 */
				reg = < 0xc000 0x1000 >;        /* in zephyr/dts/arm/nordic/nrf5340_cpuapp_peripherals.dtsi:241 */
				interrupts = < 0xc 0x1 >;       /* in zephyr/dts/arm/nordic/nrf5340_cpuapp_peripherals.dtsi:242 */
				easydma-maxcnt-bits = < 0x10 >; /* in zephyr/dts/arm/nordic/nrf5340_cpuapp_peripherals.dtsi:243 */
				status = "disabled";            /* in zephyr/dts/arm/nordic/nrf5340_cpuapp_peripherals.dtsi:244 */
				zephyr,pm-device-runtime-auto;  /* in zephyr/dts/arm/nordic/nrf5340_cpuapp_peripherals.dtsi:245 */
			};

			/* node '/soc/peripheral@50000000/spi@c000' defined in zephyr/dts/arm/nordic/nrf5340_cpuapp_peripherals.dtsi:248 */
			spi3: arduino_spi: spi@c000 {
				#address-cells = < 0x1 >;                /* in zephyr/dts/arm/nordic/nrf5340_cpuapp_peripherals.dtsi:256 */
				#size-cells = < 0x0 >;                   /* in zephyr/dts/arm/nordic/nrf5340_cpuapp_peripherals.dtsi:257 */
				reg = < 0xc000 0x1000 >;                 /* in zephyr/dts/arm/nordic/nrf5340_cpuapp_peripherals.dtsi:258 */
				interrupts = < 0xc 0x1 >;                /* in zephyr/dts/arm/nordic/nrf5340_cpuapp_peripherals.dtsi:259 */
				max-frequency = < 0x7a1200 >;            /* in zephyr/dts/arm/nordic/nrf5340_cpuapp_peripherals.dtsi:260 */
				easydma-maxcnt-bits = < 0x10 >;          /* in zephyr/dts/arm/nordic/nrf5340_cpuapp_peripherals.dtsi:261 */
				status = "disabled";                     /* in zephyr/dts/arm/nordic/nrf5340_cpuapp_peripherals.dtsi:262 */
				compatible = "nordic,nrf-spim";          /* in zephyr/boards/nordic/nrf7002dk/nrf5340_cpuapp_common.dtsi:231 */
				cs-gpios = < &arduino_header 0x10 0x1 >; /* in zephyr/boards/nordic/nrf7002dk/nrf5340_cpuapp_common.dtsi:232 */
				pinctrl-0 = < &spi3_default >;           /* in zephyr/boards/nordic/nrf7002dk/nrf5340_cpuapp_common.dtsi:233 */
				pinctrl-1 = < &spi3_sleep >;             /* in zephyr/boards/nordic/nrf7002dk/nrf5340_cpuapp_common.dtsi:234 */
				pinctrl-names = "default",
				                "sleep";                 /* in zephyr/boards/nordic/nrf7002dk/nrf5340_cpuapp_common.dtsi:235 */
			};

			/* node '/soc/peripheral@50000000/uart@c000' defined in zephyr/dts/arm/nordic/nrf5340_cpuapp_peripherals.dtsi:265 */
			uart3: uart@c000 {
				compatible = "nordic,nrf-uarte"; /* in zephyr/dts/arm/nordic/nrf5340_cpuapp_peripherals.dtsi:266 */
				reg = < 0xc000 0x1000 >;         /* in zephyr/dts/arm/nordic/nrf5340_cpuapp_peripherals.dtsi:267 */
				interrupts = < 0xc 0x1 >;        /* in zephyr/dts/arm/nordic/nrf5340_cpuapp_peripherals.dtsi:268 */
				status = "disabled";             /* in zephyr/dts/arm/nordic/nrf5340_cpuapp_peripherals.dtsi:269 */
			};

			/* node '/soc/peripheral@50000000/adc@e000' defined in zephyr/dts/arm/nordic/nrf5340_cpuapp_peripherals.dtsi:272 */
			adc: adc@e000 {
				compatible = "nordic,nrf-saadc"; /* in zephyr/dts/arm/nordic/nrf5340_cpuapp_peripherals.dtsi:273 */
				reg = < 0xe000 0x1000 >;         /* in zephyr/dts/arm/nordic/nrf5340_cpuapp_peripherals.dtsi:274 */
				interrupts = < 0xe 0x1 >;        /* in zephyr/dts/arm/nordic/nrf5340_cpuapp_peripherals.dtsi:275 */
				#io-channel-cells = < 0x1 >;     /* in zephyr/dts/arm/nordic/nrf5340_cpuapp_peripherals.dtsi:277 */
				zephyr,pm-device-runtime-auto;   /* in zephyr/dts/arm/nordic/nrf5340_cpuapp_peripherals.dtsi:278 */
				status = "okay";                 /* in zephyr/boards/nordic/nrf7002dk/nrf5340_cpuapp_common.dtsi:149 */
				phandle = < 0x18 >;              /* in zephyr/boards/nordic/nrf7002dk/nrf5340_cpuapp_common.dtsi:92 */
			};

			/* node '/soc/peripheral@50000000/timer@f000' defined in zephyr/dts/arm/nordic/nrf5340_cpuapp_peripherals.dtsi:281 */
			timer0: timer@f000 {
				compatible = "nordic,nrf-timer"; /* in zephyr/dts/arm/nordic/nrf5340_cpuapp_peripherals.dtsi:282 */
				status = "disabled";             /* in zephyr/dts/arm/nordic/nrf5340_cpuapp_peripherals.dtsi:283 */
				reg = < 0xf000 0x1000 >;         /* in zephyr/dts/arm/nordic/nrf5340_cpuapp_peripherals.dtsi:284 */
				cc-num = < 0x6 >;                /* in zephyr/dts/arm/nordic/nrf5340_cpuapp_peripherals.dtsi:285 */
				max-bit-width = < 0x20 >;        /* in zephyr/dts/arm/nordic/nrf5340_cpuapp_peripherals.dtsi:286 */
				interrupts = < 0xf 0x1 >;        /* in zephyr/dts/arm/nordic/nrf5340_cpuapp_peripherals.dtsi:287 */
				prescaler = < 0x0 >;             /* in zephyr/dts/arm/nordic/nrf5340_cpuapp_peripherals.dtsi:288 */
			};

			/* node '/soc/peripheral@50000000/timer@10000' defined in zephyr/dts/arm/nordic/nrf5340_cpuapp_peripherals.dtsi:291 */
			timer1: timer@10000 {
				compatible = "nordic,nrf-timer"; /* in zephyr/dts/arm/nordic/nrf5340_cpuapp_peripherals.dtsi:292 */
				status = "disabled";             /* in zephyr/dts/arm/nordic/nrf5340_cpuapp_peripherals.dtsi:293 */
				reg = < 0x10000 0x1000 >;        /* in zephyr/dts/arm/nordic/nrf5340_cpuapp_peripherals.dtsi:294 */
				cc-num = < 0x6 >;                /* in zephyr/dts/arm/nordic/nrf5340_cpuapp_peripherals.dtsi:295 */
				max-bit-width = < 0x20 >;        /* in zephyr/dts/arm/nordic/nrf5340_cpuapp_peripherals.dtsi:296 */
				interrupts = < 0x10 0x1 >;       /* in zephyr/dts/arm/nordic/nrf5340_cpuapp_peripherals.dtsi:297 */
				prescaler = < 0x0 >;             /* in zephyr/dts/arm/nordic/nrf5340_cpuapp_peripherals.dtsi:298 */
				phandle = < 0x14 >;              /* in zephyr/dts/vendor/nordic/nrf_common.dtsi:42 */
			};

			/* node '/soc/peripheral@50000000/timer@11000' defined in zephyr/dts/arm/nordic/nrf5340_cpuapp_peripherals.dtsi:301 */
			timer2: timer@11000 {
				compatible = "nordic,nrf-timer"; /* in zephyr/dts/arm/nordic/nrf5340_cpuapp_peripherals.dtsi:302 */
				status = "disabled";             /* in zephyr/dts/arm/nordic/nrf5340_cpuapp_peripherals.dtsi:303 */
				reg = < 0x11000 0x1000 >;        /* in zephyr/dts/arm/nordic/nrf5340_cpuapp_peripherals.dtsi:304 */
				cc-num = < 0x6 >;                /* in zephyr/dts/arm/nordic/nrf5340_cpuapp_peripherals.dtsi:305 */
				max-bit-width = < 0x20 >;        /* in zephyr/dts/arm/nordic/nrf5340_cpuapp_peripherals.dtsi:306 */
				interrupts = < 0x11 0x1 >;       /* in zephyr/dts/arm/nordic/nrf5340_cpuapp_peripherals.dtsi:307 */
				prescaler = < 0x0 >;             /* in zephyr/dts/arm/nordic/nrf5340_cpuapp_peripherals.dtsi:308 */
			};

			/* node '/soc/peripheral@50000000/rtc@14000' defined in zephyr/dts/arm/nordic/nrf5340_cpuapp_peripherals.dtsi:311 */
			rtc0: rtc@14000 {
				compatible = "nordic,nrf-rtc"; /* in zephyr/dts/arm/nordic/nrf5340_cpuapp_peripherals.dtsi:312 */
				reg = < 0x14000 0x1000 >;      /* in zephyr/dts/arm/nordic/nrf5340_cpuapp_peripherals.dtsi:313 */
				cc-num = < 0x4 >;              /* in zephyr/dts/arm/nordic/nrf5340_cpuapp_peripherals.dtsi:314 */
				interrupts = < 0x14 0x1 >;     /* in zephyr/dts/arm/nordic/nrf5340_cpuapp_peripherals.dtsi:315 */
				status = "disabled";           /* in zephyr/dts/arm/nordic/nrf5340_cpuapp_peripherals.dtsi:316 */
				clock-frequency = < 0x8000 >;  /* in zephyr/dts/arm/nordic/nrf5340_cpuapp_peripherals.dtsi:317 */
				prescaler = < 0x1 >;           /* in zephyr/dts/arm/nordic/nrf5340_cpuapp_peripherals.dtsi:318 */
			};

			/* node '/soc/peripheral@50000000/rtc@15000' defined in zephyr/dts/arm/nordic/nrf5340_cpuapp_peripherals.dtsi:321 */
			rtc1: rtc@15000 {
				compatible = "nordic,nrf-rtc"; /* in zephyr/dts/arm/nordic/nrf5340_cpuapp_peripherals.dtsi:322 */
				reg = < 0x15000 0x1000 >;      /* in zephyr/dts/arm/nordic/nrf5340_cpuapp_peripherals.dtsi:323 */
				cc-num = < 0x4 >;              /* in zephyr/dts/arm/nordic/nrf5340_cpuapp_peripherals.dtsi:324 */
				interrupts = < 0x15 0x1 >;     /* in zephyr/dts/arm/nordic/nrf5340_cpuapp_peripherals.dtsi:325 */
				status = "disabled";           /* in zephyr/dts/arm/nordic/nrf5340_cpuapp_peripherals.dtsi:326 */
				clock-frequency = < 0x8000 >;  /* in zephyr/dts/arm/nordic/nrf5340_cpuapp_peripherals.dtsi:327 */
				prescaler = < 0x1 >;           /* in zephyr/dts/arm/nordic/nrf5340_cpuapp_peripherals.dtsi:328 */
			};

			/* node '/soc/peripheral@50000000/dppic@17000' defined in zephyr/dts/arm/nordic/nrf5340_cpuapp_peripherals.dtsi:331 */
			dppic0: dppic: dppic@17000 {
				compatible = "nordic,nrf-dppic"; /* in zephyr/dts/arm/nordic/nrf5340_cpuapp_peripherals.dtsi:332 */
				reg = < 0x17000 0x1000 >;        /* in zephyr/dts/arm/nordic/nrf5340_cpuapp_peripherals.dtsi:333 */
				status = "okay";                 /* in zephyr/dts/arm/nordic/nrf5340_cpuapp_peripherals.dtsi:334 */
				channels = < 0x20 >;             /* in zephyr/dts/arm/nordic/nrf5340_cpuapp_peripherals.dtsi:335 */
				groups = < 0x6 >;                /* in zephyr/dts/arm/nordic/nrf5340_cpuapp_peripherals.dtsi:336 */
			};

			/* node '/soc/peripheral@50000000/watchdog@18000' defined in zephyr/dts/arm/nordic/nrf5340_cpuapp_peripherals.dtsi:339 */
			wdt: wdt0: watchdog@18000 {
				compatible = "nordic,nrf-wdt"; /* in zephyr/dts/arm/nordic/nrf5340_cpuapp_peripherals.dtsi:340 */
				reg = < 0x18000 0x1000 >;      /* in zephyr/dts/arm/nordic/nrf5340_cpuapp_peripherals.dtsi:341 */
				interrupts = < 0x18 0x1 >;     /* in zephyr/dts/arm/nordic/nrf5340_cpuapp_peripherals.dtsi:342 */
				status = "okay";               /* in zephyr/dts/arm/nordic/nrf5340_cpuapp_peripherals.dtsi:343 */
			};

			/* node '/soc/peripheral@50000000/watchdog@19000' defined in zephyr/dts/arm/nordic/nrf5340_cpuapp_peripherals.dtsi:346 */
			wdt1: watchdog@19000 {
				compatible = "nordic,nrf-wdt"; /* in zephyr/dts/arm/nordic/nrf5340_cpuapp_peripherals.dtsi:347 */
				reg = < 0x19000 0x1000 >;      /* in zephyr/dts/arm/nordic/nrf5340_cpuapp_peripherals.dtsi:348 */
				interrupts = < 0x19 0x1 >;     /* in zephyr/dts/arm/nordic/nrf5340_cpuapp_peripherals.dtsi:349 */
				status = "disabled";           /* in zephyr/dts/arm/nordic/nrf5340_cpuapp_peripherals.dtsi:350 */
			};

			/* node '/soc/peripheral@50000000/comparator@1a000' defined in zephyr/dts/arm/nordic/nrf5340_cpuapp_peripherals.dtsi:353 */
			comp: comparator@1a000 {
				compatible = "nordic,nrf-comp"; /* in zephyr/dts/arm/nordic/nrf5340_cpuapp_peripherals.dtsi:358 */
				reg = < 0x1a000 0x1000 >;       /* in zephyr/dts/arm/nordic/nrf5340_cpuapp_peripherals.dtsi:359 */
				interrupts = < 0x1a 0x1 >;      /* in zephyr/dts/arm/nordic/nrf5340_cpuapp_peripherals.dtsi:360 */
				status = "disabled";            /* in zephyr/dts/arm/nordic/nrf5340_cpuapp_peripherals.dtsi:361 */
			};

			/* node '/soc/peripheral@50000000/egu@1b000' defined in zephyr/dts/arm/nordic/nrf5340_cpuapp_peripherals.dtsi:364 */
			egu0: egu@1b000 {
				compatible = "nordic,nrf-egu"; /* in zephyr/dts/arm/nordic/nrf5340_cpuapp_peripherals.dtsi:365 */
				reg = < 0x1b000 0x1000 >;      /* in zephyr/dts/arm/nordic/nrf5340_cpuapp_peripherals.dtsi:366 */
				interrupts = < 0x1b 0x1 >;     /* in zephyr/dts/arm/nordic/nrf5340_cpuapp_peripherals.dtsi:367 */
				status = "okay";               /* in zephyr/dts/arm/nordic/nrf5340_cpuapp_peripherals.dtsi:368 */
			};

			/* node '/soc/peripheral@50000000/egu@1c000' defined in zephyr/dts/arm/nordic/nrf5340_cpuapp_peripherals.dtsi:371 */
			egu1: egu@1c000 {
				compatible = "nordic,nrf-egu"; /* in zephyr/dts/arm/nordic/nrf5340_cpuapp_peripherals.dtsi:372 */
				reg = < 0x1c000 0x1000 >;      /* in zephyr/dts/arm/nordic/nrf5340_cpuapp_peripherals.dtsi:373 */
				interrupts = < 0x1c 0x1 >;     /* in zephyr/dts/arm/nordic/nrf5340_cpuapp_peripherals.dtsi:374 */
				status = "okay";               /* in zephyr/dts/arm/nordic/nrf5340_cpuapp_peripherals.dtsi:375 */
			};

			/* node '/soc/peripheral@50000000/egu@1d000' defined in zephyr/dts/arm/nordic/nrf5340_cpuapp_peripherals.dtsi:378 */
			egu2: egu@1d000 {
				compatible = "nordic,nrf-egu"; /* in zephyr/dts/arm/nordic/nrf5340_cpuapp_peripherals.dtsi:379 */
				reg = < 0x1d000 0x1000 >;      /* in zephyr/dts/arm/nordic/nrf5340_cpuapp_peripherals.dtsi:380 */
				interrupts = < 0x1d 0x1 >;     /* in zephyr/dts/arm/nordic/nrf5340_cpuapp_peripherals.dtsi:381 */
				status = "okay";               /* in zephyr/dts/arm/nordic/nrf5340_cpuapp_peripherals.dtsi:382 */
			};

			/* node '/soc/peripheral@50000000/egu@1e000' defined in zephyr/dts/arm/nordic/nrf5340_cpuapp_peripherals.dtsi:385 */
			egu3: egu@1e000 {
				compatible = "nordic,nrf-egu"; /* in zephyr/dts/arm/nordic/nrf5340_cpuapp_peripherals.dtsi:386 */
				reg = < 0x1e000 0x1000 >;      /* in zephyr/dts/arm/nordic/nrf5340_cpuapp_peripherals.dtsi:387 */
				interrupts = < 0x1e 0x1 >;     /* in zephyr/dts/arm/nordic/nrf5340_cpuapp_peripherals.dtsi:388 */
				status = "okay";               /* in zephyr/dts/arm/nordic/nrf5340_cpuapp_peripherals.dtsi:389 */
			};

			/* node '/soc/peripheral@50000000/egu@1f000' defined in zephyr/dts/arm/nordic/nrf5340_cpuapp_peripherals.dtsi:392 */
			egu4: egu@1f000 {
				compatible = "nordic,nrf-egu"; /* in zephyr/dts/arm/nordic/nrf5340_cpuapp_peripherals.dtsi:393 */
				reg = < 0x1f000 0x1000 >;      /* in zephyr/dts/arm/nordic/nrf5340_cpuapp_peripherals.dtsi:394 */
				interrupts = < 0x1f 0x1 >;     /* in zephyr/dts/arm/nordic/nrf5340_cpuapp_peripherals.dtsi:395 */
				status = "okay";               /* in zephyr/dts/arm/nordic/nrf5340_cpuapp_peripherals.dtsi:396 */
			};

			/* node '/soc/peripheral@50000000/egu@20000' defined in zephyr/dts/arm/nordic/nrf5340_cpuapp_peripherals.dtsi:399 */
			egu5: egu@20000 {
				compatible = "nordic,nrf-egu"; /* in zephyr/dts/arm/nordic/nrf5340_cpuapp_peripherals.dtsi:400 */
				reg = < 0x20000 0x1000 >;      /* in zephyr/dts/arm/nordic/nrf5340_cpuapp_peripherals.dtsi:401 */
				interrupts = < 0x20 0x1 >;     /* in zephyr/dts/arm/nordic/nrf5340_cpuapp_peripherals.dtsi:402 */
				status = "okay";               /* in zephyr/dts/arm/nordic/nrf5340_cpuapp_peripherals.dtsi:403 */
			};

			/* node '/soc/peripheral@50000000/pwm@21000' defined in zephyr/dts/arm/nordic/nrf5340_cpuapp_peripherals.dtsi:406 */
			pwm0: pwm@21000 {
				compatible = "nordic,nrf-pwm"; /* in zephyr/dts/arm/nordic/nrf5340_cpuapp_peripherals.dtsi:407 */
				reg = < 0x21000 0x1000 >;      /* in zephyr/dts/arm/nordic/nrf5340_cpuapp_peripherals.dtsi:408 */
				interrupts = < 0x21 0x1 >;     /* in zephyr/dts/arm/nordic/nrf5340_cpuapp_peripherals.dtsi:409 */
				#pwm-cells = < 0x3 >;          /* in zephyr/dts/arm/nordic/nrf5340_cpuapp_peripherals.dtsi:411 */
				status = "okay";               /* in zephyr/boards/nordic/nrf7002dk/nrf5340_cpuapp_common.dtsi:185 */
				pinctrl-0 = < &pwm0_default >; /* in zephyr/boards/nordic/nrf7002dk/nrf5340_cpuapp_common.dtsi:186 */
				pinctrl-1 = < &pwm0_sleep >;   /* in zephyr/boards/nordic/nrf7002dk/nrf5340_cpuapp_common.dtsi:187 */
				pinctrl-names = "default",
				                "sleep";       /* in zephyr/boards/nordic/nrf7002dk/nrf5340_cpuapp_common.dtsi:188 */
				phandle = < 0x17 >;            /* in zephyr/boards/nordic/nrf7002dk/nrf5340_cpuapp_common.dtsi:40 */
			};

			/* node '/soc/peripheral@50000000/pwm@22000' defined in zephyr/dts/arm/nordic/nrf5340_cpuapp_peripherals.dtsi:414 */
			pwm1: pwm@22000 {
				compatible = "nordic,nrf-pwm"; /* in zephyr/dts/arm/nordic/nrf5340_cpuapp_peripherals.dtsi:415 */
				reg = < 0x22000 0x1000 >;      /* in zephyr/dts/arm/nordic/nrf5340_cpuapp_peripherals.dtsi:416 */
				interrupts = < 0x22 0x1 >;     /* in zephyr/dts/arm/nordic/nrf5340_cpuapp_peripherals.dtsi:417 */
				status = "disabled";           /* in zephyr/dts/arm/nordic/nrf5340_cpuapp_peripherals.dtsi:418 */
				#pwm-cells = < 0x3 >;          /* in zephyr/dts/arm/nordic/nrf5340_cpuapp_peripherals.dtsi:419 */
			};

			/* node '/soc/peripheral@50000000/pwm@23000' defined in zephyr/dts/arm/nordic/nrf5340_cpuapp_peripherals.dtsi:422 */
			pwm2: pwm@23000 {
				compatible = "nordic,nrf-pwm"; /* in zephyr/dts/arm/nordic/nrf5340_cpuapp_peripherals.dtsi:423 */
				reg = < 0x23000 0x1000 >;      /* in zephyr/dts/arm/nordic/nrf5340_cpuapp_peripherals.dtsi:424 */
				interrupts = < 0x23 0x1 >;     /* in zephyr/dts/arm/nordic/nrf5340_cpuapp_peripherals.dtsi:425 */
				status = "disabled";           /* in zephyr/dts/arm/nordic/nrf5340_cpuapp_peripherals.dtsi:426 */
				#pwm-cells = < 0x3 >;          /* in zephyr/dts/arm/nordic/nrf5340_cpuapp_peripherals.dtsi:427 */
			};

			/* node '/soc/peripheral@50000000/pwm@24000' defined in zephyr/dts/arm/nordic/nrf5340_cpuapp_peripherals.dtsi:430 */
			pwm3: pwm@24000 {
				compatible = "nordic,nrf-pwm"; /* in zephyr/dts/arm/nordic/nrf5340_cpuapp_peripherals.dtsi:431 */
				reg = < 0x24000 0x1000 >;      /* in zephyr/dts/arm/nordic/nrf5340_cpuapp_peripherals.dtsi:432 */
				interrupts = < 0x24 0x1 >;     /* in zephyr/dts/arm/nordic/nrf5340_cpuapp_peripherals.dtsi:433 */
				status = "disabled";           /* in zephyr/dts/arm/nordic/nrf5340_cpuapp_peripherals.dtsi:434 */
				#pwm-cells = < 0x3 >;          /* in zephyr/dts/arm/nordic/nrf5340_cpuapp_peripherals.dtsi:435 */
			};

			/* node '/soc/peripheral@50000000/pdm@26000' defined in zephyr/dts/arm/nordic/nrf5340_cpuapp_peripherals.dtsi:438 */
			pdm0: pdm@26000 {
				compatible = "nordic,nrf-pdm"; /* in zephyr/dts/arm/nordic/nrf5340_cpuapp_peripherals.dtsi:439 */
				reg = < 0x26000 0x1000 >;      /* in zephyr/dts/arm/nordic/nrf5340_cpuapp_peripherals.dtsi:440 */
				interrupts = < 0x26 0x1 >;     /* in zephyr/dts/arm/nordic/nrf5340_cpuapp_peripherals.dtsi:441 */
				status = "disabled";           /* in zephyr/dts/arm/nordic/nrf5340_cpuapp_peripherals.dtsi:442 */
			};

			/* node '/soc/peripheral@50000000/i2s@28000' defined in zephyr/dts/arm/nordic/nrf5340_cpuapp_peripherals.dtsi:445 */
			i2s0: i2s@28000 {
				compatible = "nordic,nrf-i2s"; /* in zephyr/dts/arm/nordic/nrf5340_cpuapp_peripherals.dtsi:446 */
				#address-cells = < 0x1 >;      /* in zephyr/dts/arm/nordic/nrf5340_cpuapp_peripherals.dtsi:447 */
				#size-cells = < 0x0 >;         /* in zephyr/dts/arm/nordic/nrf5340_cpuapp_peripherals.dtsi:448 */
				reg = < 0x28000 0x1000 >;      /* in zephyr/dts/arm/nordic/nrf5340_cpuapp_peripherals.dtsi:449 */
				interrupts = < 0x28 0x1 >;     /* in zephyr/dts/arm/nordic/nrf5340_cpuapp_peripherals.dtsi:450 */
				status = "disabled";           /* in zephyr/dts/arm/nordic/nrf5340_cpuapp_peripherals.dtsi:451 */
			};

			/* node '/soc/peripheral@50000000/mbox@2a000' defined in zephyr/dts/arm/nordic/nrf5340_cpuapp_peripherals.dtsi:454 */
			mbox: ipc: mbox@2a000 {
				compatible = "nordic,mbox-nrf-ipc",
				             "nordic,nrf-ipc";      /* in zephyr/dts/arm/nordic/nrf5340_cpuapp_peripherals.dtsi:455 */
				reg = < 0x2a000 0x1000 >;           /* in zephyr/dts/arm/nordic/nrf5340_cpuapp_peripherals.dtsi:456 */
				tx-mask = < 0xffff >;               /* in zephyr/dts/arm/nordic/nrf5340_cpuapp_peripherals.dtsi:457 */
				rx-mask = < 0xffff >;               /* in zephyr/dts/arm/nordic/nrf5340_cpuapp_peripherals.dtsi:458 */
				interrupts = < 0x2a 0x1 >;          /* in zephyr/dts/arm/nordic/nrf5340_cpuapp_peripherals.dtsi:459 */
				#mbox-cells = < 0x1 >;              /* in zephyr/dts/arm/nordic/nrf5340_cpuapp_peripherals.dtsi:460 */
				status = "okay";                    /* in zephyr/dts/arm/nordic/nrf5340_cpuapp_peripherals.dtsi:461 */
				phandle = < 0x16 >;                 /* in zephyr/dts/arm/nordic/nrf5340_cpuapp_ipc.dtsi:10 */
			};

			/* node '/soc/peripheral@50000000/qspi@2b000' defined in zephyr/dts/arm/nordic/nrf5340_cpuapp_peripherals.dtsi:464 */
			qspi: qspi@2b000 {
				compatible = "nordic,nrf-qspi";  /* in zephyr/dts/arm/nordic/nrf5340_cpuapp_peripherals.dtsi:465 */
				#address-cells = < 0x1 >;        /* in zephyr/dts/arm/nordic/nrf5340_cpuapp_peripherals.dtsi:466 */
				#size-cells = < 0x0 >;           /* in zephyr/dts/arm/nordic/nrf5340_cpuapp_peripherals.dtsi:467 */
				reg = < 0x2b000 0x1000 >,
				      < 0x10000000 0x10000000 >; /* in zephyr/dts/arm/nordic/nrf5340_cpuapp_peripherals.dtsi:468 */
				reg-names = "qspi",
				            "qspi_mm";           /* in zephyr/dts/arm/nordic/nrf5340_cpuapp_peripherals.dtsi:469 */
				interrupts = < 0x2b 0x1 >;       /* in zephyr/dts/arm/nordic/nrf5340_cpuapp_peripherals.dtsi:470 */
				status = "okay";                 /* in zephyr/boards/nordic/nrf7002dk/nrf5340_cpuapp_common.dtsi:216 */
				pinctrl-0 = < &qspi_default >;   /* in zephyr/boards/nordic/nrf7002dk/nrf5340_cpuapp_common.dtsi:217 */
				pinctrl-1 = < &qspi_sleep >;     /* in zephyr/boards/nordic/nrf7002dk/nrf5340_cpuapp_common.dtsi:218 */
				pinctrl-names = "default",
				                "sleep";         /* in zephyr/boards/nordic/nrf7002dk/nrf5340_cpuapp_common.dtsi:219 */

				/* node '/soc/peripheral@50000000/qspi@2b000/nrf7002@1' defined in zephyr/boards/nordic/nrf7002dk/nrf7002dk_nrf5340_cpuapp.dts:27 */
				nrf70: nrf7002@1 {
					compatible = "nordic,nrf7002-qspi";     /* in zephyr/boards/nordic/nrf7002dk/nrf7002dk_nrf5340_cpuapp.dts:28 */
					status = "okay";                        /* in zephyr/boards/nordic/nrf7002dk/nrf7002dk_nrf5340_cpuapp.dts:29 */
					reg = < 0x1 >;                          /* in zephyr/boards/nordic/nrf7002dk/nrf7002dk_nrf5340_cpuapp.dts:30 */
					qspi-frequency = < 0x16e3600 >;         /* in zephyr/boards/nordic/nrf7002dk/nrf7002dk_nrf5340_cpuapp.dts:31 */
					qspi-quad-mode;                         /* in zephyr/boards/nordic/nrf7002dk/nrf7002dk_nrf5340_cpuapp.dts:32 */
					iovdd-ctrl-gpios = < &gpio0 0x1f 0x0 >; /* in zephyr/boards/nordic/nrf7002dk/nrf70_common.dtsi:7 */
					bucken-gpios = < &gpio0 0xc 0x0 >;      /* in zephyr/boards/nordic/nrf7002dk/nrf70_common.dtsi:8 */
					host-irq-gpios = < &gpio0 0x17 0x0 >;   /* in zephyr/boards/nordic/nrf7002dk/nrf70_common.dtsi:9 */
					srrf-switch-gpios = < &gpio1 0xa 0x0 >; /* in zephyr/boards/nordic/nrf7002dk/nrf70_common.dtsi:10 */
					wifi-max-tx-pwr-2g-dsss = < 0x15 >;     /* in zephyr/boards/nordic/nrf7002dk/nrf70_common.dtsi:12 */
					wifi-max-tx-pwr-2g-mcs0 = < 0x10 >;     /* in zephyr/boards/nordic/nrf7002dk/nrf70_common.dtsi:13 */
					wifi-max-tx-pwr-2g-mcs7 = < 0x10 >;     /* in zephyr/boards/nordic/nrf7002dk/nrf70_common.dtsi:14 */
					wifi-max-tx-pwr-5g-low-mcs0 = < 0x9 >;  /* in zephyr/boards/nordic/nrf7002dk/nrf70_common_5g.dtsi:7 */
					wifi-max-tx-pwr-5g-low-mcs7 = < 0x9 >;  /* in zephyr/boards/nordic/nrf7002dk/nrf70_common_5g.dtsi:8 */
					wifi-max-tx-pwr-5g-mid-mcs0 = < 0xb >;  /* in zephyr/boards/nordic/nrf7002dk/nrf70_common_5g.dtsi:9 */
					wifi-max-tx-pwr-5g-mid-mcs7 = < 0xb >;  /* in zephyr/boards/nordic/nrf7002dk/nrf70_common_5g.dtsi:10 */
					wifi-max-tx-pwr-5g-high-mcs0 = < 0xd >; /* in zephyr/boards/nordic/nrf7002dk/nrf70_common_5g.dtsi:11 */
					wifi-max-tx-pwr-5g-high-mcs7 = < 0xd >; /* in zephyr/boards/nordic/nrf7002dk/nrf70_common_5g.dtsi:12 */

					/* node '/soc/peripheral@50000000/qspi@2b000/nrf7002@1/wlan0' defined in zephyr/boards/nordic/nrf7002dk/nrf70_common.dtsi:16 */
					wlan0: wlan0 {
						compatible = "nordic,wlan"; /* in zephyr/boards/nordic/nrf7002dk/nrf70_common.dtsi:17 */
					};

					/* node '/soc/peripheral@50000000/qspi@2b000/nrf7002@1/wlan1' defined in zephyr/boards/nordic/nrf7002dk/nrf70_common.dtsi:20 */
					wlan1: wlan1 {
						compatible = "nordic,wlan"; /* in zephyr/boards/nordic/nrf7002dk/nrf70_common.dtsi:21 */
					};
				};
			};

			/* node '/soc/peripheral@50000000/nfct@2d000' defined in zephyr/dts/arm/nordic/nrf5340_cpuapp_peripherals.dtsi:474 */
			nfct: nfct@2d000 {
				compatible = "nordic,nrf-nfct"; /* in zephyr/dts/arm/nordic/nrf5340_cpuapp_peripherals.dtsi:475 */
				reg = < 0x2d000 0x1000 >;       /* in zephyr/dts/arm/nordic/nrf5340_cpuapp_peripherals.dtsi:476 */
				interrupts = < 0x2d 0x1 >;      /* in zephyr/dts/arm/nordic/nrf5340_cpuapp_peripherals.dtsi:477 */
				status = "okay";                /* in zephyr/boards/nordic/nrf7002dk/nrf5340_cpuapp_common.dtsi:153 */
			};

			/* node '/soc/peripheral@50000000/mutex@30000' defined in zephyr/dts/arm/nordic/nrf5340_cpuapp_peripherals.dtsi:481 */
			mutex: mutex@30000 {
				compatible = "nordic,nrf-mutex"; /* in zephyr/dts/arm/nordic/nrf5340_cpuapp_peripherals.dtsi:482 */
				reg = < 0x30000 0x1000 >;        /* in zephyr/dts/arm/nordic/nrf5340_cpuapp_peripherals.dtsi:483 */
				status = "okay";                 /* in zephyr/dts/arm/nordic/nrf5340_cpuapp_peripherals.dtsi:484 */
			};

			/* node '/soc/peripheral@50000000/qdec@33000' defined in zephyr/dts/arm/nordic/nrf5340_cpuapp_peripherals.dtsi:487 */
			qdec0: qdec@33000 {
				compatible = "nordic,nrf-qdec"; /* in zephyr/dts/arm/nordic/nrf5340_cpuapp_peripherals.dtsi:488 */
				reg = < 0x33000 0x1000 >;       /* in zephyr/dts/arm/nordic/nrf5340_cpuapp_peripherals.dtsi:489 */
				interrupts = < 0x33 0x1 >;      /* in zephyr/dts/arm/nordic/nrf5340_cpuapp_peripherals.dtsi:490 */
				status = "disabled";            /* in zephyr/dts/arm/nordic/nrf5340_cpuapp_peripherals.dtsi:491 */
			};

			/* node '/soc/peripheral@50000000/qdec@34000' defined in zephyr/dts/arm/nordic/nrf5340_cpuapp_peripherals.dtsi:494 */
			qdec1: qdec@34000 {
				compatible = "nordic,nrf-qdec"; /* in zephyr/dts/arm/nordic/nrf5340_cpuapp_peripherals.dtsi:495 */
				reg = < 0x34000 0x1000 >;       /* in zephyr/dts/arm/nordic/nrf5340_cpuapp_peripherals.dtsi:496 */
				interrupts = < 0x34 0x1 >;      /* in zephyr/dts/arm/nordic/nrf5340_cpuapp_peripherals.dtsi:497 */
				status = "disabled";            /* in zephyr/dts/arm/nordic/nrf5340_cpuapp_peripherals.dtsi:498 */
			};

			/* node '/soc/peripheral@50000000/usbd@36000' defined in zephyr/dts/arm/nordic/nrf5340_cpuapp_peripherals.dtsi:501 */
			usbd: zephyr_udc0: usbd@36000 {
				reg = < 0x36000 0x1000 >;       /* in zephyr/dts/arm/nordic/nrf5340_cpuapp_peripherals.dtsi:503 */
				interrupts = < 0x36 0x1 >;      /* in zephyr/dts/arm/nordic/nrf5340_cpuapp_peripherals.dtsi:504 */
				num-bidir-endpoints = < 0x1 >;  /* in zephyr/dts/arm/nordic/nrf5340_cpuapp_peripherals.dtsi:505 */
				num-in-endpoints = < 0x7 >;     /* in zephyr/dts/arm/nordic/nrf5340_cpuapp_peripherals.dtsi:506 */
				num-out-endpoints = < 0x7 >;    /* in zephyr/dts/arm/nordic/nrf5340_cpuapp_peripherals.dtsi:507 */
				num-isoin-endpoints = < 0x1 >;  /* in zephyr/dts/arm/nordic/nrf5340_cpuapp_peripherals.dtsi:508 */
				num-isoout-endpoints = < 0x1 >; /* in zephyr/dts/arm/nordic/nrf5340_cpuapp_peripherals.dtsi:509 */
				compatible = "nordic,nrf-usbd"; /* in zephyr/boards/nordic/nrf7002dk/nrf5340_cpuapp_common.dtsi:243 */
				status = "okay";                /* in zephyr/boards/nordic/nrf7002dk/nrf5340_cpuapp_common.dtsi:244 */
			};

			/* node '/soc/peripheral@50000000/regulator@37000' defined in zephyr/dts/arm/nordic/nrf5340_cpuapp_peripherals.dtsi:513 */
			usbreg: regulator@37000 {
				compatible = "nordic,nrf-usbreg"; /* in zephyr/dts/arm/nordic/nrf5340_cpuapp_peripherals.dtsi:514 */
				reg = < 0x37000 0x1000 >;         /* in zephyr/dts/arm/nordic/nrf5340_cpuapp_peripherals.dtsi:515 */
				interrupts = < 0x37 0x1 >;        /* in zephyr/dts/arm/nordic/nrf5340_cpuapp_peripherals.dtsi:516 */
				status = "okay";                  /* in zephyr/dts/arm/nordic/nrf5340_cpuapp_peripherals.dtsi:517 */
			};

			/* node '/soc/peripheral@50000000/kmu@39000' defined in zephyr/dts/arm/nordic/nrf5340_cpuapp_peripherals.dtsi:520 */
			kmu: kmu@39000 {
				compatible = "nordic,nrf-kmu"; /* in zephyr/dts/arm/nordic/nrf5340_cpuapp_peripherals.dtsi:521 */
				reg = < 0x39000 0x1000 >;      /* in zephyr/dts/arm/nordic/nrf5340_cpuapp_peripherals.dtsi:522 */
				interrupts = < 0x39 0x1 >;     /* in zephyr/dts/arm/nordic/nrf5340_cpuapp_peripherals.dtsi:523 */
				status = "okay";               /* in zephyr/dts/arm/nordic/nrf5340_cpuapp_peripherals.dtsi:524 */
			};

			/* node '/soc/peripheral@50000000/vmc@81000' defined in zephyr/dts/arm/nordic/nrf5340_cpuapp_peripherals.dtsi:527 */
			vmc: vmc@81000 {
				compatible = "nordic,nrf-vmc"; /* in zephyr/dts/arm/nordic/nrf5340_cpuapp_peripherals.dtsi:528 */
				reg = < 0x81000 0x1000 >;      /* in zephyr/dts/arm/nordic/nrf5340_cpuapp_peripherals.dtsi:529 */
				status = "okay";               /* in zephyr/dts/arm/nordic/nrf5340_cpuapp_peripherals.dtsi:530 */
			};

			/* node '/soc/peripheral@50000000/gpio@842500' defined in zephyr/dts/arm/nordic/nrf5340_cpuapp_peripherals.dtsi:533 */
			gpio0: gpio@842500 {
				compatible = "nordic,nrf-gpio"; /* in zephyr/dts/arm/nordic/nrf5340_cpuapp_peripherals.dtsi:534 */
				gpio-controller;                /* in zephyr/dts/arm/nordic/nrf5340_cpuapp_peripherals.dtsi:535 */
				reg = < 0x842500 0x300 >;       /* in zephyr/dts/arm/nordic/nrf5340_cpuapp_peripherals.dtsi:536 */
				#gpio-cells = < 0x2 >;          /* in zephyr/dts/arm/nordic/nrf5340_cpuapp_peripherals.dtsi:537 */
				port = < 0x0 >;                 /* in zephyr/dts/arm/nordic/nrf5340_cpuapp_peripherals.dtsi:539 */
				gpiote-instance = < &gpiote >;  /* in zephyr/dts/arm/nordic/nrf5340_cpuapp_peripherals.dtsi:540 */
				status = "okay";                /* in zephyr/boards/nordic/nrf7002dk/nrf5340_cpuapp_common.dtsi:161 */
				phandle = < 0xa >;              /* in zephyr/boards/nordic/nrf7002dk/nrf5340_cpuapp_common.dtsi:197 */
			};

			/* node '/soc/peripheral@50000000/gpio@842800' defined in zephyr/dts/arm/nordic/nrf5340_cpuapp_peripherals.dtsi:543 */
			gpio1: gpio@842800 {
				compatible = "nordic,nrf-gpio"; /* in zephyr/dts/arm/nordic/nrf5340_cpuapp_peripherals.dtsi:544 */
				gpio-controller;                /* in zephyr/dts/arm/nordic/nrf5340_cpuapp_peripherals.dtsi:545 */
				reg = < 0x842800 0x300 >;       /* in zephyr/dts/arm/nordic/nrf5340_cpuapp_peripherals.dtsi:546 */
				#gpio-cells = < 0x2 >;          /* in zephyr/dts/arm/nordic/nrf5340_cpuapp_peripherals.dtsi:547 */
				ngpios = < 0x10 >;              /* in zephyr/dts/arm/nordic/nrf5340_cpuapp_peripherals.dtsi:548 */
				port = < 0x1 >;                 /* in zephyr/dts/arm/nordic/nrf5340_cpuapp_peripherals.dtsi:550 */
				gpiote-instance = < &gpiote >;  /* in zephyr/dts/arm/nordic/nrf5340_cpuapp_peripherals.dtsi:551 */
				status = "okay";                /* in zephyr/boards/nordic/nrf7002dk/nrf5340_cpuapp_common.dtsi:165 */
				phandle = < 0x12 >;             /* in zephyr/boards/nordic/nrf7002dk/nrf70_common.dtsi:10 */
			};

			/* node '/soc/peripheral@50000000/ieee802154' defined in zephyr/dts/arm/nordic/nrf5340_cpuapp_peripherals.dtsi:554 */
			ieee802154: ieee802154 {
				compatible = "nordic,nrf-ieee802154"; /* in zephyr/dts/arm/nordic/nrf5340_cpuapp_peripherals.dtsi:555 */
				status = "okay";                      /* in zephyr/boards/nordic/nrf7002dk/nrf5340_cpuapp_common.dtsi:239 */
			};
		};

		/* node '/soc/flash-controller@50039000' defined in zephyr/dts/arm/nordic/nrf5340_cpuapp.dtsi:80 */
		flash_controller: flash-controller@50039000 {
			compatible = "nordic,nrf53-flash-controller"; /* in zephyr/dts/arm/nordic/nrf5340_cpuapp.dtsi:81 */
			reg = < 0x50039000 0x1000 >;                  /* in zephyr/dts/arm/nordic/nrf5340_cpuapp.dtsi:82 */
			ranges;                                       /* in zephyr/dts/arm/nordic/nrf5340_cpuapp.dtsi:83 */
			partial-erase;                                /* in zephyr/dts/arm/nordic/nrf5340_cpuapp.dtsi:84 */
			#address-cells = < 0x1 >;                     /* in zephyr/dts/arm/nordic/nrf5340_cpuapp.dtsi:85 */
			#size-cells = < 0x1 >;                        /* in zephyr/dts/arm/nordic/nrf5340_cpuapp.dtsi:86 */

			/* node '/soc/flash-controller@50039000/flash@0' defined in zephyr/dts/arm/nordic/nrf5340_cpuapp.dtsi:88 */
			flash0: flash@0 {
				compatible = "soc-nv-flash";   /* in zephyr/dts/arm/nordic/nrf5340_cpuapp.dtsi:89 */
				erase-block-size = < 0x1000 >; /* in zephyr/dts/arm/nordic/nrf5340_cpuapp.dtsi:90 */
				write-block-size = < 0x4 >;    /* in zephyr/dts/arm/nordic/nrf5340_cpuapp.dtsi:91 */
				reg = < 0x0 0x100000 >;        /* in zephyr/dts/arm/nordic/nrf5340_cpuapp.dtsi:92 */
				ranges = < 0x0 0x0 0x100000 >; /* in zephyr/dts/arm/nordic/nrf5340_cpuapp.dtsi:93 */
				status = "okay";               /* in zephyr/dts/arm/nordic/nrf5340_cpuapp.dtsi:94 */
				#address-cells = < 0x1 >;      /* in zephyr/dts/arm/nordic/nrf5340_cpuapp.dtsi:95 */
				#size-cells = < 0x1 >;         /* in zephyr/dts/arm/nordic/nrf5340_cpuapp.dtsi:96 */

				/* node '/soc/flash-controller@50039000/flash@0/partitions' defined in zephyr/dts/vendor/nordic/nrf5340_cpuapp_partition.dtsi:11 */
				partitions {
					ranges;                   /* in zephyr/dts/vendor/nordic/nrf5340_cpuapp_partition.dtsi:12 */
					#address-cells = < 0x1 >; /* in zephyr/dts/vendor/nordic/nrf5340_cpuapp_partition.dtsi:13 */
					#size-cells = < 0x1 >;    /* in zephyr/dts/vendor/nordic/nrf5340_cpuapp_partition.dtsi:14 */

					/* node '/soc/flash-controller@50039000/flash@0/partitions/partition@0' defined in zephyr/dts/vendor/nordic/nrf5340_cpuapp_partition.dtsi:16 */
					boot_partition: partition@0 {
						compatible = "zephyr,mapped-partition"; /* in zephyr/dts/vendor/nordic/nrf5340_cpuapp_partition.dtsi:17 */
						label = "mcuboot";                      /* in zephyr/dts/vendor/nordic/nrf5340_cpuapp_partition.dtsi:18 */
						reg = < 0x0 0x10000 >;                  /* in zephyr/dts/vendor/nordic/nrf5340_cpuapp_partition.dtsi:19 */
					};

					/* node '/soc/flash-controller@50039000/flash@0/partitions/partition@10000' defined in zephyr/dts/vendor/nordic/nrf5340_cpuapp_partition.dtsi:22 */
					slot0_partition: partition@10000 {
						compatible = "zephyr,mapped-partition"; /* in zephyr/dts/vendor/nordic/nrf5340_cpuapp_partition.dtsi:23 */
						label = "image-0";                      /* in zephyr/dts/vendor/nordic/nrf5340_cpuapp_partition.dtsi:24 */
						reg = < 0x10000 0x74000 >;              /* in zephyr/dts/vendor/nordic/nrf5340_cpuapp_partition.dtsi:25 */
					};

					/* node '/soc/flash-controller@50039000/flash@0/partitions/partition@84000' defined in zephyr/dts/vendor/nordic/nrf5340_cpuapp_partition.dtsi:28 */
					slot1_partition: partition@84000 {
						compatible = "zephyr,mapped-partition"; /* in zephyr/dts/vendor/nordic/nrf5340_cpuapp_partition.dtsi:29 */
						label = "image-1";                      /* in zephyr/dts/vendor/nordic/nrf5340_cpuapp_partition.dtsi:30 */
						reg = < 0x84000 0x74000 >;              /* in zephyr/dts/vendor/nordic/nrf5340_cpuapp_partition.dtsi:31 */
					};

					/* node '/soc/flash-controller@50039000/flash@0/partitions/partition@f8000' defined in zephyr/dts/vendor/nordic/nrf5340_cpuapp_partition.dtsi:34 */
					storage_partition: partition@f8000 {
						compatible = "zephyr,mapped-partition"; /* in zephyr/dts/vendor/nordic/nrf5340_cpuapp_partition.dtsi:35 */
						label = "storage";                      /* in zephyr/dts/vendor/nordic/nrf5340_cpuapp_partition.dtsi:36 */
						reg = < 0xf8000 0x8000 >;               /* in zephyr/dts/vendor/nordic/nrf5340_cpuapp_partition.dtsi:37 */
					};
				};
			};
		};

		/* node '/soc/spu@50003000' defined in zephyr/dts/arm/nordic/nrf5340_cpuapp.dtsi:102 */
		spu: spu@50003000 {
			compatible = "nordic,nrf-spu"; /* in zephyr/dts/arm/nordic/nrf5340_cpuapp.dtsi:103 */
			reg = < 0x50003000 0x1000 >;   /* in zephyr/dts/arm/nordic/nrf5340_cpuapp.dtsi:104 */
			interrupts = < 0x3 0x1 >;      /* in zephyr/dts/arm/nordic/nrf5340_cpuapp.dtsi:105 */
			status = "okay";               /* in zephyr/dts/arm/nordic/nrf5340_cpuapp.dtsi:106 */
		};

		/* node '/soc/gpiote@5000d000' defined in zephyr/dts/arm/nordic/nrf5340_cpuapp.dtsi:114 */
		gpiote: gpiote0: gpiote@5000d000 {
			compatible = "nordic,nrf-gpiote"; /* in zephyr/dts/arm/nordic/nrf5340_cpuapp.dtsi:115 */
			reg = < 0x5000d000 0x1000 >;      /* in zephyr/dts/arm/nordic/nrf5340_cpuapp.dtsi:116 */
			interrupts = < 0xd 0x5 >;         /* in zephyr/dts/arm/nordic/nrf5340_cpuapp.dtsi:117 */
			instance = < 0x0 >;               /* in zephyr/dts/arm/nordic/nrf5340_cpuapp.dtsi:119 */
			status = "okay";                  /* in zephyr/boards/nordic/nrf7002dk/nrf5340_cpuapp_common.dtsi:157 */
			phandle = < 0x13 >;               /* in zephyr/dts/arm/nordic/nrf5340_cpuapp_peripherals.dtsi:540 */
		};

		/* node '/soc/gpiote@4002f000' defined in zephyr/dts/arm/nordic/nrf5340_cpuapp.dtsi:123 */
		gpiote1: gpiote@4002f000 {
			compatible = "nordic,nrf-gpiote"; /* in zephyr/dts/arm/nordic/nrf5340_cpuapp.dtsi:124 */
			reg = < 0x4002f000 0x1000 >;      /* in zephyr/dts/arm/nordic/nrf5340_cpuapp.dtsi:125 */
			interrupts = < 0x2f 0x5 >;        /* in zephyr/dts/arm/nordic/nrf5340_cpuapp.dtsi:126 */
			status = "disabled";              /* in zephyr/dts/arm/nordic/nrf5340_cpuapp.dtsi:127 */
			instance = < 0x1 >;               /* in zephyr/dts/arm/nordic/nrf5340_cpuapp.dtsi:128 */
		};

		/* node '/soc/crypto@50844000' defined in zephyr/dts/arm/nordic/nrf5340_cpuapp.dtsi:131 */
		cryptocell: crypto@50844000 {
			compatible = "arm,cryptocell-312"; /* in zephyr/dts/arm/nordic/nrf5340_cpuapp.dtsi:132 */
			reg = < 0x50844000 0x1000 >,
			      < 0x50845000 0x1000 >;       /* in zephyr/dts/arm/nordic/nrf5340_cpuapp.dtsi:133 */
			reg-names = "wrapper",
			            "core";                /* in zephyr/dts/arm/nordic/nrf5340_cpuapp.dtsi:134 */
			interrupts = < 0x44 0x1 >;         /* in zephyr/dts/arm/nordic/nrf5340_cpuapp.dtsi:135 */
			status = "okay";                   /* in zephyr/dts/arm/nordic/nrf5340_cpuapp.dtsi:136 */
		};
	};

	/* node '/pin-controller' defined in zephyr/dts/vendor/nordic/nrf_common.dtsi:26 */
	pinctrl: pin-controller {
		compatible = "nordic,nrf-pinctrl"; /* in zephyr/dts/vendor/nordic/nrf_common.dtsi:31 */

		/* node '/pin-controller/i2c1_default' defined in zephyr/boards/nordic/nrf7002dk/nrf5340_cpuapp_common_pinctrl.dtsi:7 */
		i2c1_default: i2c1_default {
			phandle = < 0x4 >; /* in zephyr/boards/nordic/nrf7002dk/nrf5340_cpuapp_common.dtsi:171 */

			/* node '/pin-controller/i2c1_default/group1' defined in zephyr/boards/nordic/nrf7002dk/nrf5340_cpuapp_common_pinctrl.dtsi:8 */
			group1 {
				psels = < 0xc000022 >,
				        < 0xb000023 >; /* in zephyr/boards/nordic/nrf7002dk/nrf5340_cpuapp_common_pinctrl.dtsi:9 */
			};
		};

		/* node '/pin-controller/i2c1_sleep' defined in zephyr/boards/nordic/nrf7002dk/nrf5340_cpuapp_common_pinctrl.dtsi:14 */
		i2c1_sleep: i2c1_sleep {
			phandle = < 0x5 >; /* in zephyr/boards/nordic/nrf7002dk/nrf5340_cpuapp_common.dtsi:172 */

			/* node '/pin-controller/i2c1_sleep/group1' defined in zephyr/boards/nordic/nrf7002dk/nrf5340_cpuapp_common_pinctrl.dtsi:15 */
			group1 {
				psels = < 0xc000022 >,
				        < 0xb000023 >; /* in zephyr/boards/nordic/nrf7002dk/nrf5340_cpuapp_common_pinctrl.dtsi:16 */
				low-power-enable;      /* in zephyr/boards/nordic/nrf7002dk/nrf5340_cpuapp_common_pinctrl.dtsi:18 */
			};
		};

		/* node '/pin-controller/uart0_default' defined in zephyr/boards/nordic/nrf7002dk/nrf5340_cpuapp_common_pinctrl.dtsi:22 */
		uart0_default: uart0_default {
			phandle = < 0x2 >; /* in zephyr/boards/nordic/nrf7002dk/nrf5340_cpuapp_common.dtsi:179 */

			/* node '/pin-controller/uart0_default/group1' defined in zephyr/boards/nordic/nrf7002dk/nrf5340_cpuapp_common_pinctrl.dtsi:23 */
			group1 {
				psels = < 0x14 >,
				        < 0x2000013 >; /* in zephyr/boards/nordic/nrf7002dk/nrf5340_cpuapp_common_pinctrl.dtsi:24 */
			};

			/* node '/pin-controller/uart0_default/group2' defined in zephyr/boards/nordic/nrf7002dk/nrf5340_cpuapp_common_pinctrl.dtsi:28 */
			group2 {
				psels = < 0x1000016 >,
				        < 0x3000015 >; /* in zephyr/boards/nordic/nrf7002dk/nrf5340_cpuapp_common_pinctrl.dtsi:29 */
				bias-pull-up;          /* in zephyr/boards/nordic/nrf7002dk/nrf5340_cpuapp_common_pinctrl.dtsi:31 */
			};
		};

		/* node '/pin-controller/uart0_sleep' defined in zephyr/boards/nordic/nrf7002dk/nrf5340_cpuapp_common_pinctrl.dtsi:35 */
		uart0_sleep: uart0_sleep {
			phandle = < 0x3 >; /* in zephyr/boards/nordic/nrf7002dk/nrf5340_cpuapp_common.dtsi:180 */

			/* node '/pin-controller/uart0_sleep/group1' defined in zephyr/boards/nordic/nrf7002dk/nrf5340_cpuapp_common_pinctrl.dtsi:36 */
			group1 {
				psels = < 0x1000016 >,
				        < 0x2000013 >,
				        < 0x3000015 >; /* in zephyr/boards/nordic/nrf7002dk/nrf5340_cpuapp_common_pinctrl.dtsi:37 */
				low-power-enable;      /* in zephyr/boards/nordic/nrf7002dk/nrf5340_cpuapp_common_pinctrl.dtsi:40 */
			};

			/* node '/pin-controller/uart0_sleep/group2' defined in zephyr/boards/nordic/nrf7002dk/nrf5340_cpuapp_common_pinctrl.dtsi:43 */
			group2 {
				psels = < 0x14 >; /* in zephyr/boards/nordic/nrf7002dk/nrf5340_cpuapp_common_pinctrl.dtsi:44 */
				low-power-enable; /* in zephyr/boards/nordic/nrf7002dk/nrf5340_cpuapp_common_pinctrl.dtsi:45 */
				bias-pull-up;     /* in zephyr/boards/nordic/nrf7002dk/nrf5340_cpuapp_common_pinctrl.dtsi:46 */
			};
		};

		/* node '/pin-controller/pwm0_default' defined in zephyr/boards/nordic/nrf7002dk/nrf5340_cpuapp_common_pinctrl.dtsi:50 */
		pwm0_default: pwm0_default {
			phandle = < 0xe >; /* in zephyr/boards/nordic/nrf7002dk/nrf5340_cpuapp_common.dtsi:186 */

			/* node '/pin-controller/pwm0_default/group1' defined in zephyr/boards/nordic/nrf7002dk/nrf5340_cpuapp_common_pinctrl.dtsi:51 */
			group1 {
				psels = < 0x16000026 >; /* in zephyr/boards/nordic/nrf7002dk/nrf5340_cpuapp_common_pinctrl.dtsi:52 */
			};
		};

		/* node '/pin-controller/pwm0_sleep' defined in zephyr/boards/nordic/nrf7002dk/nrf5340_cpuapp_common_pinctrl.dtsi:56 */
		pwm0_sleep: pwm0_sleep {
			phandle = < 0xf >; /* in zephyr/boards/nordic/nrf7002dk/nrf5340_cpuapp_common.dtsi:187 */

			/* node '/pin-controller/pwm0_sleep/group1' defined in zephyr/boards/nordic/nrf7002dk/nrf5340_cpuapp_common_pinctrl.dtsi:57 */
			group1 {
				psels = < 0x16000026 >; /* in zephyr/boards/nordic/nrf7002dk/nrf5340_cpuapp_common_pinctrl.dtsi:58 */
				low-power-enable;       /* in zephyr/boards/nordic/nrf7002dk/nrf5340_cpuapp_common_pinctrl.dtsi:59 */
			};
		};

		/* node '/pin-controller/qspi_default' defined in zephyr/boards/nordic/nrf7002dk/nrf5340_cpuapp_common_pinctrl.dtsi:63 */
		qspi_default: qspi_default {
			phandle = < 0x10 >; /* in zephyr/boards/nordic/nrf7002dk/nrf5340_cpuapp_common.dtsi:217 */

			/* node '/pin-controller/qspi_default/group1' defined in zephyr/boards/nordic/nrf7002dk/nrf5340_cpuapp_common_pinctrl.dtsi:64 */
			group1 {
				psels = < 0x1d000011 >,
				        < 0x1f00000d >,
				        < 0x2000000e >,
				        < 0x2100000f >,
				        < 0x22000010 >; /* in zephyr/boards/nordic/nrf7002dk/nrf5340_cpuapp_common_pinctrl.dtsi:65 */
				bias-pull-down;         /* in zephyr/boards/nordic/nrf7002dk/nrf5340_cpuapp_common_pinctrl.dtsi:70 */
			};

			/* node '/pin-controller/qspi_default/group2' defined in zephyr/boards/nordic/nrf7002dk/nrf5340_cpuapp_common_pinctrl.dtsi:73 */
			group2 {
				psels = < 0x1e000012 >; /* in zephyr/boards/nordic/nrf7002dk/nrf5340_cpuapp_common_pinctrl.dtsi:74 */
				bias-pull-up;           /* in zephyr/boards/nordic/nrf7002dk/nrf5340_cpuapp_common_pinctrl.dtsi:75 */
			};
		};

		/* node '/pin-controller/qspi_sleep' defined in zephyr/boards/nordic/nrf7002dk/nrf5340_cpuapp_common_pinctrl.dtsi:79 */
		qspi_sleep: qspi_sleep {
			phandle = < 0x11 >; /* in zephyr/boards/nordic/nrf7002dk/nrf5340_cpuapp_common.dtsi:218 */

			/* node '/pin-controller/qspi_sleep/group1' defined in zephyr/boards/nordic/nrf7002dk/nrf5340_cpuapp_common_pinctrl.dtsi:80 */
			group1 {
				psels = < 0x1d000011 >,
				        < 0x1f00000d >,
				        < 0x2000000e >,
				        < 0x2100000f >,
				        < 0x22000010 >; /* in zephyr/boards/nordic/nrf7002dk/nrf5340_cpuapp_common_pinctrl.dtsi:81 */
				bias-pull-down;         /* in zephyr/boards/nordic/nrf7002dk/nrf5340_cpuapp_common_pinctrl.dtsi:86 */
				low-power-enable;       /* in zephyr/boards/nordic/nrf7002dk/nrf5340_cpuapp_common_pinctrl.dtsi:87 */
			};

			/* node '/pin-controller/qspi_sleep/group2' defined in zephyr/boards/nordic/nrf7002dk/nrf5340_cpuapp_common_pinctrl.dtsi:90 */
			group2 {
				psels = < 0x1e000012 >; /* in zephyr/boards/nordic/nrf7002dk/nrf5340_cpuapp_common_pinctrl.dtsi:91 */
				bias-pull-up;           /* in zephyr/boards/nordic/nrf7002dk/nrf5340_cpuapp_common_pinctrl.dtsi:92 */
				low-power-enable;       /* in zephyr/boards/nordic/nrf7002dk/nrf5340_cpuapp_common_pinctrl.dtsi:93 */
			};
		};

		/* node '/pin-controller/uart1_default' defined in zephyr/boards/nordic/nrf7002dk/nrf5340_cpuapp_common_pinctrl.dtsi:97 */
		uart1_default: uart1_default {
			phandle = < 0x6 >; /* in zephyr/boards/nordic/nrf7002dk/nrf5340_cpuapp_common.dtsi:225 */

			/* node '/pin-controller/uart1_default/group1' defined in zephyr/boards/nordic/nrf7002dk/nrf5340_cpuapp_common_pinctrl.dtsi:98 */
			group1 {
				psels = < 0x21 >; /* in zephyr/boards/nordic/nrf7002dk/nrf5340_cpuapp_common_pinctrl.dtsi:99 */
			};

			/* node '/pin-controller/uart1_default/group2' defined in zephyr/boards/nordic/nrf7002dk/nrf5340_cpuapp_common_pinctrl.dtsi:102 */
			group2 {
				psels = < 0x1000020 >; /* in zephyr/boards/nordic/nrf7002dk/nrf5340_cpuapp_common_pinctrl.dtsi:103 */
				bias-pull-up;          /* in zephyr/boards/nordic/nrf7002dk/nrf5340_cpuapp_common_pinctrl.dtsi:104 */
			};
		};

		/* node '/pin-controller/uart1_sleep' defined in zephyr/boards/nordic/nrf7002dk/nrf5340_cpuapp_common_pinctrl.dtsi:108 */
		uart1_sleep: uart1_sleep {
			phandle = < 0x7 >; /* in zephyr/boards/nordic/nrf7002dk/nrf5340_cpuapp_common.dtsi:226 */

			/* node '/pin-controller/uart1_sleep/group1' defined in zephyr/boards/nordic/nrf7002dk/nrf5340_cpuapp_common_pinctrl.dtsi:109 */
			group1 {
				psels = < 0x21 >,
				        < 0x1000020 >; /* in zephyr/boards/nordic/nrf7002dk/nrf5340_cpuapp_common_pinctrl.dtsi:110 */
				low-power-enable;      /* in zephyr/boards/nordic/nrf7002dk/nrf5340_cpuapp_common_pinctrl.dtsi:112 */
			};
		};

		/* node '/pin-controller/spi3_default' defined in zephyr/boards/nordic/nrf7002dk/nrf5340_cpuapp_common_pinctrl.dtsi:116 */
		spi3_default: spi3_default {
			phandle = < 0xc >; /* in zephyr/boards/nordic/nrf7002dk/nrf5340_cpuapp_common.dtsi:233 */

			/* node '/pin-controller/spi3_default/group1' defined in zephyr/boards/nordic/nrf7002dk/nrf5340_cpuapp_common_pinctrl.dtsi:117 */
			group1 {
				psels = < 0x400002f >,
				        < 0x600002e >,
				        < 0x500002d >;       /* in zephyr/boards/nordic/nrf7002dk/nrf5340_cpuapp_common_pinctrl.dtsi:118 */
				nordic,drive-mode = < 0x3 >; /* in zephyr/boards/nordic/nrf7002dk/nrf5340_cpuapp_common_pinctrl.dtsi:121 */
			};
		};

		/* node '/pin-controller/spi3_sleep' defined in zephyr/boards/nordic/nrf7002dk/nrf5340_cpuapp_common_pinctrl.dtsi:125 */
		spi3_sleep: spi3_sleep {
			phandle = < 0xd >; /* in zephyr/boards/nordic/nrf7002dk/nrf5340_cpuapp_common.dtsi:234 */

			/* node '/pin-controller/spi3_sleep/group1' defined in zephyr/boards/nordic/nrf7002dk/nrf5340_cpuapp_common_pinctrl.dtsi:126 */
			group1 {
				psels = < 0x400002f >,
				        < 0x600002e >,
				        < 0x500002d >; /* in zephyr/boards/nordic/nrf7002dk/nrf5340_cpuapp_common_pinctrl.dtsi:127 */
				low-power-enable;      /* in zephyr/boards/nordic/nrf7002dk/nrf5340_cpuapp_common_pinctrl.dtsi:130 */
			};
		};

		/* node '/pin-controller/spi4_default' defined in zephyr/boards/nordic/nrf7002dk/nrf5340_cpuapp_common_pinctrl.dtsi:134 */
		spi4_default: spi4_default {
			phandle = < 0x8 >; /* in zephyr/boards/nordic/nrf7002dk/nrf5340_cpuapp_common.dtsi:194 */

			/* node '/pin-controller/spi4_default/group1' defined in zephyr/boards/nordic/nrf7002dk/nrf5340_cpuapp_common_pinctrl.dtsi:135 */
			group1 {
				psels = < 0x4000008 >,
				        < 0x600000a >,
				        < 0x5000009 >; /* in zephyr/boards/nordic/nrf7002dk/nrf5340_cpuapp_common_pinctrl.dtsi:136 */
			};
		};

		/* node '/pin-controller/spi4_sleep' defined in zephyr/boards/nordic/nrf7002dk/nrf5340_cpuapp_common_pinctrl.dtsi:142 */
		spi4_sleep: spi4_sleep {
			phandle = < 0x9 >; /* in zephyr/boards/nordic/nrf7002dk/nrf5340_cpuapp_common.dtsi:195 */

			/* node '/pin-controller/spi4_sleep/group1' defined in zephyr/boards/nordic/nrf7002dk/nrf5340_cpuapp_common_pinctrl.dtsi:143 */
			group1 {
				psels = < 0x4000008 >,
				        < 0x600000a >,
				        < 0x5000009 >; /* in zephyr/boards/nordic/nrf7002dk/nrf5340_cpuapp_common_pinctrl.dtsi:144 */
				low-power-enable;      /* in zephyr/boards/nordic/nrf7002dk/nrf5340_cpuapp_common_pinctrl.dtsi:147 */
			};
		};

		/* node '/pin-controller/spi2_default' defined in zephyr/boards/nordic/nrf7002dk/nrf7002dk_nrf5340_cpuapp_pinctrl.dtsi:2 */
		spi2_default: spi2_default {

			/* node '/pin-controller/spi2_default/group1' defined in zephyr/boards/nordic/nrf7002dk/nrf7002dk_nrf5340_cpuapp_pinctrl.dtsi:3 */
			group1 {
				psels = < 0x400002f >,
				        < 0x600002e >,
				        < 0x500002d >; /* in zephyr/boards/nordic/nrf7002dk/nrf7002dk_nrf5340_cpuapp_pinctrl.dtsi:4 */
			};
		};

		/* node '/pin-controller/spi2_sleep' defined in zephyr/boards/nordic/nrf7002dk/nrf7002dk_nrf5340_cpuapp_pinctrl.dtsi:10 */
		spi2_sleep: spi2_sleep {

			/* node '/pin-controller/spi2_sleep/group1' defined in zephyr/boards/nordic/nrf7002dk/nrf7002dk_nrf5340_cpuapp_pinctrl.dtsi:11 */
			group1 {
				psels = < 0x400002f >,
				        < 0x600002e >,
				        < 0x500002d >; /* in zephyr/boards/nordic/nrf7002dk/nrf7002dk_nrf5340_cpuapp_pinctrl.dtsi:12 */
				low-power-enable;      /* in zephyr/boards/nordic/nrf7002dk/nrf7002dk_nrf5340_cpuapp_pinctrl.dtsi:15 */
			};
		};
	};

	/* node '/entropy_bt_hci' defined in zephyr/dts/vendor/nordic/nrf_common.dtsi:34 */
	rng_hci: entropy_bt_hci {
		compatible = "zephyr,bt-hci-entropy"; /* in zephyr/dts/vendor/nordic/nrf_common.dtsi:35 */
		status = "okay";                      /* in zephyr/dts/arm/nordic/nrf5340_cpuapp.dtsi:148 */
	};

	/* node '/sw-pwm' defined in zephyr/dts/vendor/nordic/nrf_common.dtsi:39 */
	sw_pwm: sw-pwm {
		compatible = "nordic,nrf-sw-pwm"; /* in zephyr/dts/vendor/nordic/nrf_common.dtsi:40 */
		status = "disabled";              /* in zephyr/dts/vendor/nordic/nrf_common.dtsi:41 */
		generator = < &timer1 >;          /* in zephyr/dts/vendor/nordic/nrf_common.dtsi:42 */
		clock-prescaler = < 0x0 >;        /* in zephyr/dts/vendor/nordic/nrf_common.dtsi:43 */
		#pwm-cells = < 0x3 >;             /* in zephyr/dts/vendor/nordic/nrf_common.dtsi:44 */
	};

	/* node '/clocks' defined in zephyr/dts/arm/nordic/nrf5340_clocks.dtsi:8 */
	clocks {

		/* node '/clocks/lfxo' defined in zephyr/dts/arm/nordic/nrf5340_clocks.dtsi:9 */
		lfxo: lfxo {
			compatible = "nordic,nrf53-lfxo";     /* in zephyr/dts/arm/nordic/nrf5340_clocks.dtsi:10 */
			#clock-cells = < 0x0 >;               /* in zephyr/dts/arm/nordic/nrf5340_clocks.dtsi:11 */
			clock-frequency = < 0x8000 >;         /* in zephyr/dts/arm/nordic/nrf5340_clocks.dtsi:12 */
			load-capacitors = "internal";         /* in zephyr/boards/nordic/nrf7002dk/nrf5340_cpuapp_common.dtsi:144 */
			load-capacitance-picofarad = < 0x7 >; /* in zephyr/boards/nordic/nrf7002dk/nrf5340_cpuapp_common.dtsi:145 */
		};

		/* node '/clocks/hfxo' defined in zephyr/dts/arm/nordic/nrf5340_clocks.dtsi:15 */
		hfxo: hfxo {
			compatible = "nordic,nrf53-hfxo"; /* in zephyr/dts/arm/nordic/nrf5340_clocks.dtsi:16 */
			#clock-cells = < 0x0 >;           /* in zephyr/dts/arm/nordic/nrf5340_clocks.dtsi:17 */
			clock-frequency = < 0x1e84800 >;  /* in zephyr/dts/arm/nordic/nrf5340_clocks.dtsi:18 */
			startup-time-us = < 0x578 >;      /* in zephyr/dts/arm/nordic/nrf5340_clocks.dtsi:19 */
		};
	};

	/* node '/cpus' defined in zephyr/dts/arm/nordic/nrf5340_cpuapp.dtsi:13 */
	cpus {
		#address-cells = < 0x1 >; /* in zephyr/dts/arm/nordic/nrf5340_cpuapp.dtsi:14 */
		#size-cells = < 0x0 >;    /* in zephyr/dts/arm/nordic/nrf5340_cpuapp.dtsi:15 */

		/* node '/cpus/cpu@0' defined in zephyr/dts/arm/nordic/nrf5340_cpuapp.dtsi:17 */
		cpu0: cpu@0 {
			device_type = "cpu";            /* in zephyr/dts/arm/nordic/nrf5340_cpuapp.dtsi:18 */
			compatible = "arm,cortex-m33f"; /* in zephyr/dts/arm/nordic/nrf5340_cpuapp.dtsi:19 */
			reg = < 0x0 >;                  /* in zephyr/dts/arm/nordic/nrf5340_cpuapp.dtsi:20 */
			#address-cells = < 0x1 >;       /* in zephyr/dts/arm/nordic/nrf5340_cpuapp.dtsi:21 */
			#size-cells = < 0x1 >;          /* in zephyr/dts/arm/nordic/nrf5340_cpuapp.dtsi:22 */

			/* node '/cpus/cpu@0/itm@e0000000' defined in zephyr/dts/arm/nordic/nrf5340_cpuapp.dtsi:24 */
			itm: itm@e0000000 {
				compatible = "arm,armv8m-itm";     /* in zephyr/dts/arm/nordic/nrf5340_cpuapp.dtsi:25 */
				reg = < 0xe0000000 0x1000 >;       /* in zephyr/dts/arm/nordic/nrf5340_cpuapp.dtsi:26 */
				swo-ref-frequency = < 0x3d09000 >; /* in zephyr/dts/arm/nordic/nrf5340_cpuapp.dtsi:27 */
			};

			/* node '/cpus/cpu@0/mpu@e000ed90' defined in zephyr/dts/arm/nordic/nrf5340_cpuapp.dtsi:30 */
			mpu: mpu@e000ed90 {
				compatible = "arm,armv8m-mpu"; /* in zephyr/dts/arm/nordic/nrf5340_cpuapp.dtsi:31 */
				reg = < 0xe000ed90 0x40 >;     /* in zephyr/dts/arm/nordic/nrf5340_cpuapp.dtsi:32 */
			};
		};
	};

	/* node '/ipc' defined in zephyr/dts/arm/nordic/nrf5340_cpuapp.dtsi:141 */
	ipc {

		/* node '/ipc/ipc0' defined in zephyr/dts/arm/nordic/nrf5340_cpuapp_ipc.dtsi:7 */
		ipc0: ipc0 {
			compatible = "zephyr,ipc-openamp-static-vrings"; /* in zephyr/dts/arm/nordic/nrf5340_cpuapp_ipc.dtsi:8 */
			memory-region = < &sram0_shared >;               /* in zephyr/dts/arm/nordic/nrf5340_cpuapp_ipc.dtsi:9 */
			mboxes = < &mbox 0x0 >,
			         < &mbox 0x1 >;                          /* in zephyr/dts/arm/nordic/nrf5340_cpuapp_ipc.dtsi:10 */
			mbox-names = "tx",
			             "rx";                               /* in zephyr/dts/arm/nordic/nrf5340_cpuapp_ipc.dtsi:11 */
			role = "host";                                   /* in zephyr/dts/arm/nordic/nrf5340_cpuapp_ipc.dtsi:12 */
			status = "okay";                                 /* in zephyr/dts/arm/nordic/nrf5340_cpuapp_ipc.dtsi:13 */

			/* node '/ipc/ipc0/bt_hci_ipc0' defined in zephyr/dts/arm/nordic/nrf5340_cpuapp_ipc.dtsi:15 */
			bt_hci_ipc0: bt_hci_ipc0 {
				compatible = "zephyr,bt-hci-ipc"; /* in zephyr/dts/arm/nordic/nrf5340_cpuapp_ipc.dtsi:16 */
				status = "okay";                  /* in zephyr/dts/arm/nordic/nrf5340_cpuapp_ipc.dtsi:17 */
			};
		};
	};

	/* node '/leds' defined in zephyr/boards/nordic/nrf7002dk/nrf5340_cpuapp_common.dtsi:22 */
	leds {
		compatible = "gpio-leds"; /* in zephyr/boards/nordic/nrf7002dk/nrf5340_cpuapp_common.dtsi:23 */

		/* node '/leds/led_0' defined in zephyr/boards/nordic/nrf7002dk/nrf5340_cpuapp_common.dtsi:25 */
		led0: led_0 {
			gpios = < &gpio1 0x6 0x0 >; /* in zephyr/boards/nordic/nrf7002dk/nrf5340_cpuapp_common.dtsi:26 */
			label = "Green LED 0";      /* in zephyr/boards/nordic/nrf7002dk/nrf5340_cpuapp_common.dtsi:27 */
		};

		/* node '/leds/led_1' defined in zephyr/boards/nordic/nrf7002dk/nrf5340_cpuapp_common.dtsi:30 */
		led1: led_1 {
			gpios = < &gpio1 0x7 0x0 >; /* in zephyr/boards/nordic/nrf7002dk/nrf5340_cpuapp_common.dtsi:31 */
			label = "Green LED 1";      /* in zephyr/boards/nordic/nrf7002dk/nrf5340_cpuapp_common.dtsi:32 */
		};
	};

	/* node '/pwmleds' defined in zephyr/boards/nordic/nrf7002dk/nrf5340_cpuapp_common.dtsi:36 */
	pwmleds {
		compatible = "pwm-leds"; /* in zephyr/boards/nordic/nrf7002dk/nrf5340_cpuapp_common.dtsi:37 */

		/* node '/pwmleds/pwm_led_0' defined in zephyr/boards/nordic/nrf7002dk/nrf5340_cpuapp_common.dtsi:39 */
		pwm_led0: pwm_led_0 {
			pwms = < &pwm0 0x0 0x1312d00 0x0 >; /* in zephyr/boards/nordic/nrf7002dk/nrf5340_cpuapp_common.dtsi:40 */
		};
	};

	/* node '/buttons' defined in zephyr/boards/nordic/nrf7002dk/nrf5340_cpuapp_common.dtsi:44 */
	buttons {
		compatible = "gpio-keys"; /* in zephyr/boards/nordic/nrf7002dk/nrf5340_cpuapp_common.dtsi:45 */

		/* node '/buttons/button_0' defined in zephyr/boards/nordic/nrf7002dk/nrf5340_cpuapp_common.dtsi:47 */
		button0: button_0 {
			gpios = < &gpio1 0x8 0x11 >; /* in zephyr/boards/nordic/nrf7002dk/nrf5340_cpuapp_common.dtsi:48 */
			label = "Push button 1";     /* in zephyr/boards/nordic/nrf7002dk/nrf5340_cpuapp_common.dtsi:49 */
			zephyr,code = < 0xb >;       /* in zephyr/boards/nordic/nrf7002dk/nrf5340_cpuapp_common.dtsi:50 */
		};

		/* node '/buttons/button_1' defined in zephyr/boards/nordic/nrf7002dk/nrf5340_cpuapp_common.dtsi:53 */
		button1: button_1 {
			gpios = < &gpio1 0x9 0x11 >; /* in zephyr/boards/nordic/nrf7002dk/nrf5340_cpuapp_common.dtsi:54 */
			label = "Push button 2";     /* in zephyr/boards/nordic/nrf7002dk/nrf5340_cpuapp_common.dtsi:55 */
			zephyr,code = < 0x2 >;       /* in zephyr/boards/nordic/nrf7002dk/nrf5340_cpuapp_common.dtsi:56 */
		};
	};

	/* node '/connector' defined in zephyr/boards/nordic/nrf7002dk/nrf5340_cpuapp_common.dtsi:60 */
	arduino_header: connector {
		compatible = "arduino-header-r3";          /* in zephyr/boards/nordic/nrf7002dk/nrf5340_cpuapp_common.dtsi:61 */
		#gpio-cells = < 0x2 >;                     /* in zephyr/boards/nordic/nrf7002dk/nrf5340_cpuapp_common.dtsi:62 */
		gpio-map-mask = < 0xffffffff 0xffffffc0 >; /* in zephyr/boards/nordic/nrf7002dk/nrf5340_cpuapp_common.dtsi:63 */
		gpio-map-pass-thru = < 0x0 0x3f >;         /* in zephyr/boards/nordic/nrf7002dk/nrf5340_cpuapp_common.dtsi:64 */
		gpio-map = < 0x0 0x0 &gpio0 0x4 0x0 >,
		           < 0x1 0x0 &gpio0 0x5 0x0 >,
		           < 0x2 0x0 &gpio0 0x6 0x0 >,
		           < 0x3 0x0 &gpio0 0x7 0x0 >,
		           < 0x4 0x0 &gpio0 0x19 0x0 >,
		           < 0x5 0x0 &gpio0 0x1a 0x0 >,
		           < 0x6 0x0 &gpio1 0x0 0x0 >,
		           < 0x7 0x0 &gpio1 0x1 0x0 >,
		           < 0x8 0x0 &gpio1 0x4 0x0 >,
		           < 0x9 0x0 &gpio1 0x5 0x0 >,
		           < 0xa 0x0 &gpio1 0x6 0x0 >,
		           < 0xb 0x0 &gpio1 0x7 0x0 >,
		           < 0xc 0x0 &gpio1 0x8 0x0 >,
		           < 0xd 0x0 &gpio1 0x9 0x0 >,
		           < 0xe 0x0 &gpio1 0xa 0x0 >,
		           < 0xf 0x0 &gpio1 0xb 0x0 >,
		           < 0x10 0x0 &gpio1 0xc 0x0 >,
		           < 0x11 0x0 &gpio1 0xd 0x0 >,
		           < 0x12 0x0 &gpio1 0xe 0x0 >,
		           < 0x13 0x0 &gpio1 0xf 0x0 >,
		           < 0x14 0x0 &gpio1 0x2 0x0 >,
		           < 0x15 0x0 &gpio1 0x3 0x0 >;    /* in zephyr/boards/nordic/nrf7002dk/nrf5340_cpuapp_common.dtsi:65 */
		phandle = < 0xb >;                         /* in zephyr/boards/nordic/nrf7002dk/nrf5340_cpuapp_common.dtsi:232 */
	};

	/* node '/analog-connector' defined in zephyr/boards/nordic/nrf7002dk/nrf5340_cpuapp_common.dtsi:89 */
	arduino_adc: analog-connector {
		compatible = "arduino,uno-adc";    /* in zephyr/boards/nordic/nrf7002dk/nrf5340_cpuapp_common.dtsi:90 */
		#io-channel-cells = < 0x1 >;       /* in zephyr/boards/nordic/nrf7002dk/nrf5340_cpuapp_common.dtsi:91 */
		io-channel-map = < 0x0 &adc 0x0 >,
		                 < 0x1 &adc 0x1 >,
		                 < 0x2 &adc 0x2 >,
		                 < 0x3 &adc 0x3 >,
		                 < 0x4 &adc 0x4 >,
		                 < 0x5 &adc 0x5 >; /* in zephyr/boards/nordic/nrf7002dk/nrf5340_cpuapp_common.dtsi:92 */
	};

	/* node '/nrf-gpio-forwarder' defined in zephyr/boards/nordic/nrf7002dk/nrf5340_cpuapp_common.dtsi:100 */
	gpio_fwd: nrf-gpio-forwarder {
		compatible = "nordic,nrf-gpio-forwarder"; /* in zephyr/boards/nordic/nrf7002dk/nrf5340_cpuapp_common.dtsi:101 */
		status = "okay";                          /* in zephyr/boards/nordic/nrf7002dk/nrf5340_cpuapp_common.dtsi:102 */

		/* node '/nrf-gpio-forwarder/uart' defined in zephyr/boards/nordic/nrf7002dk/nrf5340_cpuapp_common.dtsi:104 */
		uart {
			gpios = < &gpio1 0x1 0x0 >,
			        < &gpio1 0x0 0x0 >,
			        < &gpio1 0x5 0x0 >,
			        < &gpio1 0x4 0x0 >; /* in zephyr/boards/nordic/nrf7002dk/nrf5340_cpuapp_common.dtsi:105 */
		};
	};

	/* node '/coex' defined in zephyr/boards/nordic/nrf7002dk/nrf5340_cpuapp_common.dtsi:121 */
	nrf_radio_coex: coex {
		status = "okay";                     /* in zephyr/boards/nordic/nrf7002dk/nrf5340_cpuapp_common.dtsi:122 */
		compatible = "nordic,nrf7002-coex";  /* in zephyr/boards/nordic/nrf7002dk/nrf5340_cpuapp_common.dtsi:123 */
		req-gpios = < &gpio0 0x1c 0x0 >;     /* in zephyr/boards/nordic/nrf7002dk/nrf5340_cpuapp_common.dtsi:124 */
		status0-gpios = < &gpio0 0x1e 0x0 >; /* in zephyr/boards/nordic/nrf7002dk/nrf5340_cpuapp_common.dtsi:125 */
		grant-gpios = < &gpio0 0x18 0x21 >;  /* in zephyr/boards/nordic/nrf7002dk/nrf5340_cpuapp_common.dtsi:126 */
		swctrl1-gpios = < &gpio0 0x1d 0x0 >; /* in zephyr/boards/nordic/nrf7002dk/nrf5340_cpuapp_common.dtsi:127 */
	};
};
